VERSION ""

NS_ :

BS_:

BU_: Instruments

BO_ 1522 AC_HSC1_FrP00: 1 Vector__XXX
 SG_ keep_network_AC_HS : 0|1@0+ (1,0) [0|1] ""  Instruments
 SG_ keep_network_AC_HS_UB : 1|1@0+ (1,0) [0|1] ""  Instruments

BO_ 1205 AC_HSC1_FrS01: 1 Vector__XXX
 SG_ wake_network_AC_HS : 0|1@0+ (1,0) [0|1] ""  Instruments
 SG_ wake_network_AC_HS_UB : 1|1@0+ (1,0) [0|1] ""  Instruments

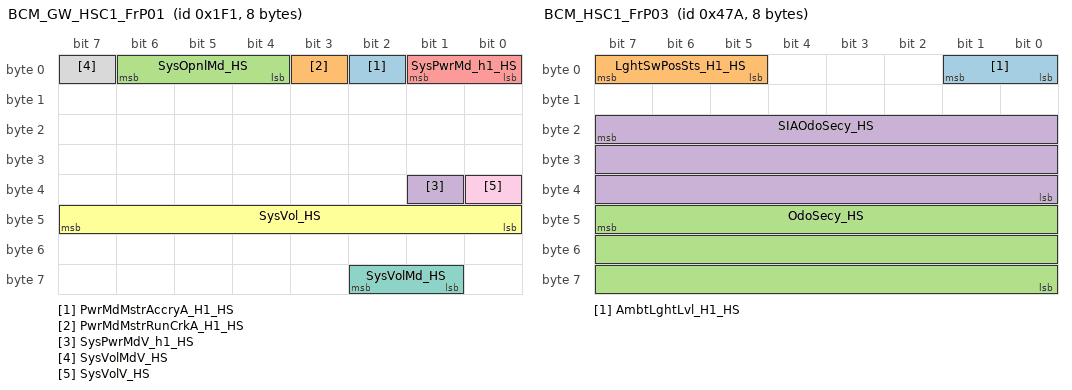
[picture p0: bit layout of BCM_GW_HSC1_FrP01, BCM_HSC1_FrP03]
BO_ 497 BCM_GW_HSC1_FrP01: 8 Vector__XXX
 SG_ PwrMdMstrAccryA_H1_HS : 2|1@0+ (1,0) [0|1] ""  Instruments
 SG_ PwrMdMstrRunCrkA_H1_HS : 3|1@0+ (1,0) [0|1] ""  Instruments
 SG_ SysOpnlMd_HS : 6|3@0+ (1,0) [0|7] ""  Instruments
 SG_ SysPwrMdV_h1_HS : 33|1@0+ (1,0) [0|1] ""  Instruments
 SG_ SysPwrMd_h1_HS : 1|2@0+ (1,0) [0|3] ""  Instruments
 SG_ SysVol_HS : 47|8@0+ (0.1,3) [3|28.5] "V"  Instruments
 SG_ SysVolMd_HS : 58|2@0+ (1,0) [0|3] ""  Instruments
 SG_ SysVolMdV_HS : 7|1@0+ (1,0) [0|1] ""  Instruments
 SG_ SysVolV_HS : 32|1@0+ (1,0) [0|1] ""  Instruments

BO_ 1344 BCM_GW_HSC1_FrP07: 8 Vector__XXX
 SG_ VehOdoV_H1_HS : 31|1@0+ (1,0) [0|1] ""  Instruments
 SG_ VehOdo_H1_HS : 7|24@0+ (1,0) [0|16777200] ""  Instruments

BO_ 795 BCM_GW_HSC1_FrP09: 8 Vector__XXX
 SG_ PwrMdMstrAccryWkupA_HS : 22|1@0+ (1,0) [0|1] ""  Instruments
 SG_ PwrMdMstrIgnA_HS : 23|1@0+ (1,0) [0|1] ""  Instruments

BO_ 1055 BCM_HSC1_FrI01: 3 Vector__XXX
 SG_ network_mode : 7|8@0+ (1,0) [0|255] ""  Instruments
 SG_ signal_config_id : 15|16@0+ (1,0) [0|65535] ""  Instruments

BO_ 1139 BCM_HSC1_FrP02: 8 Vector__XXX
 SG_ VINBCM_H1_HS : 7|64@0+ (1,0) [0|0] ""  Instruments

BO_ 1146 BCM_HSC1_FrP03: 8 Vector__XXX
 SG_ AmbtLghtLvl_H1_HS : 1|2@0+ (1,0) [0|3] ""  Instruments
 SG_ LghtSwPosSts_H1_HS : 7|3@0+ (1,0) [0|7] ""  Instruments
 SG_ OdoSecy_HS : 47|24@0+ (1,0) [0|16777200] "km"  Instruments
 SG_ SIAOdoSecy_HS : 23|24@0+ (1,0) [0|16777200] "km"  Instruments

BO_ 1130 BCM_HSC1_FrP04: 8 Vector__XXX
 SG_ BCMEmgcSp_HS : 56|1@0+ (1,0) [0|1] ""  Instruments
 SG_ BCMPwrMdHwdSta_HS : 50|2@0+ (1,0) [0|3] ""  Instruments
 SG_ BCMPwrMdHwdStaV_HS : 48|1@0+ (1,0) [0|1] ""  Instruments
 SG_ BCMSSBA_HS : 57|1@0+ (1,0) [0|1] ""  Instruments
 SG_ BCMSSBAV_HS : 58|1@0+ (1,0) [0|1] ""  Instruments
 SG_ BntOpenSts_H1_HS : 45|2@0+ (1,0) [0|3] ""  Instruments
 SG_ DipdBeamLghtOn_HS : 63|1@0+ (1,0) [0|1] ""  Instruments
 SG_ DrvrDoorOpenSts_H1_HS : 47|2@0+ (1,0) [0|3] ""  Instruments
 SG_ FrtFogLghtOn_H1_HS : 62|1@0+ (1,0) [0|1] ""  Instruments
 SG_ FrtPsngDoorOpenSts_H1_HS : 43|2@0+ (1,0) [0|3] ""  Instruments
 SG_ LDircnIO_HS : 37|1@0+ (1,0) [0|1] ""  Instruments
 SG_ LdspcOpenSts_H1_HS : 33|2@0+ (1,0) [0|3] ""  Instruments
 SG_ MainBeamLghtOn_H1_HS : 36|1@0+ (1,0) [0|1] ""  Instruments
 SG_ RDircnIO_HS : 38|1@0+ (1,0) [0|1] ""  Instruments
 SG_ RRDoorOpenSts_HS : 41|2@0+ (1,0) [0|3] ""  Instruments
 SG_ RrFogLghtF_H1_HS : 35|1@0+ (1,0) [0|1] ""  Instruments
 SG_ RrFogLghtOn_H1_HS : 39|1@0+ (1,0) [0|1] ""  Instruments
 SG_ VehLckngSta_H1_HS : 55|3@0+ (1,0) [0|7] ""  Instruments
 SG_ VehSideLghtSts_H1_HS : 52|2@0+ (1,0) [0|3] ""  Instruments

BO_ 540 BCM_HSC1_FrP06: 8 Vector__XXX
 SG_ BCMGearShftParkNtrlESR_HS : 24|1@0+ (1,0) [0|1] ""  Instruments
 SG_ BCMNoSmtKeyInVehRmndr_HS : 13|1@0+ (1,0) [0|1] ""  Instruments
 SG_ BCMNoSmtKeyPressBrkTRR_HS : 15|1@0+ (1,0) [0|1] ""  Instruments
 SG_ BCMNoSmtKeyPressClToRR_HS : 14|1@0+ (1,0) [0|1] ""  Instruments
 SG_ BCMPressBrkRmndr_HS : 28|1@0+ (1,0) [0|1] ""  Instruments
 SG_ BCMPressClRmndr_HS : 27|1@0+ (1,0) [0|1] ""  Instruments
 SG_ BCMPutSmtKeyToBkupPosR_HS : 12|1@0+ (1,0) [0|1] ""  Instruments
 SG_ BCMRunCrkF_HS : 56|1@0+ (1,0) [0|1] ""  Instruments
 SG_ BCMShftParkRmndr_HS : 38|1@0+ (1,0) [0|1] ""  Instruments
 SG_ BCMSSBFltSts_HS : 7|3@0+ (1,0) [0|7] ""  Instruments
 SG_ BCMTakeSmtKeyOutOfSR_HS : 26|1@0+ (1,0) [0|1] ""  Instruments
 SG_ DayTimeRunningLghtF_HS : 30|1@0+ (1,0) [0|1] ""  Instruments
 SG_ DrvrWndOpenRmndr_HS : 11|1@0+ (1,0) [0|1] ""  Instruments
 SG_ FrtSideLghtF_HS : 52|1@0+ (1,0) [0|1] ""  Instruments
 SG_ LBrkLghtF_HS : 23|1@0+ (1,0) [0|1] ""  Instruments
 SG_ LDipdBeamLghtF_HS : 22|1@0+ (1,0) [0|1] ""  Instruments
 SG_ LDircnIndLghtF_H1_HS : 21|1@0+ (1,0) [0|1] ""  Instruments
 SG_ PEPSAntFlt_HS : 57|1@0+ (1,0) [0|1] ""  Instruments
 SG_ RBrkLghtF_HS : 19|1@0+ (1,0) [0|1] ""  Instruments
 SG_ RDipdBeamLghtF_HS : 18|1@0+ (1,0) [0|1] ""  Instruments
 SG_ RDircnIndLghtF_H1_HS : 17|1@0+ (1,0) [0|1] ""  Instruments
 SG_ RevsLghtF_H1_HS : 31|1@0+ (1,0) [0|1] ""  Instruments
 SG_ RrSideLghtF_HS : 53|1@0+ (1,0) [0|1] ""  Instruments
 SG_ ScurtAlrmSts_HS : 2|3@0+ (1,0) [0|7] ""  Instruments
 SG_ ScurtKeyBatLow_HS : 3|1@0+ (1,0) [0|1] ""  Instruments
 SG_ ScurtKeyInvd_HS : 35|1@0+ (1,0) [0|1] ""  Instruments
 SG_ ShifterLckRlseBrkReqA_HS : 39|1@0+ (1,0) [0|1] ""  Instruments
 SG_ SrfOpenRmndr_HS : 8|1@0+ (1,0) [0|1] ""  Instruments
 SG_ SSBEnOffRmndr_HS : 33|2@0+ (1,0) [0|3] ""  Instruments
 SG_ TakeKeyOutRmndr_HS : 25|1@0+ (1,0) [0|1] ""  Instruments

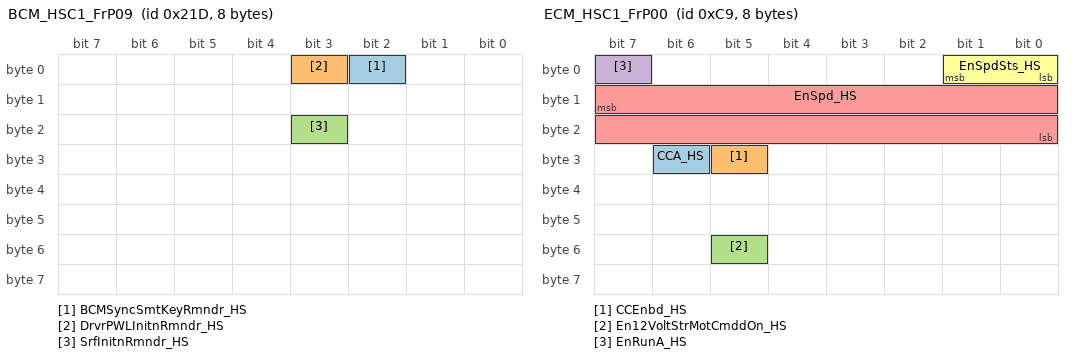
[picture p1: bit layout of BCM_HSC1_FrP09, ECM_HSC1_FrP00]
BO_ 541 BCM_HSC1_FrP09: 8 Vector__XXX
 SG_ BCMSyncSmtKeyRmndr_HS : 2|1@0+ (1,0) [0|1] ""  Instruments
 SG_ DrvrPWLInitnRmndr_HS : 3|1@0+ (1,0) [0|1] ""  Instruments
 SG_ SrfInitnRmndr_HS : 19|1@0+ (1,0) [0|1] ""  Instruments

BO_ 793 BCM_PMDC_HSC1_FrP01: 8 Vector__XXX
 SG_ BatVol_HS : 37|14@0+ (0.00097656,3) [3|18] "V"  Instruments

BO_ 814 BCM_PMDC_HSC1_FrP02: 8 Vector__XXX
 SG_ BatAgngSta_HS : 23|3@0+ (1,0) [0|7] ""  Instruments
 SG_ GenrSta_HS : 7|3@0+ (1,0) [0|7] ""  Instruments

BO_ 1303 BCM_PMDC_HSC1_FrP03: 8 Vector__XXX
 SG_ BatSOC_HS : 15|8@0+ (0.4,0) [0|100] "%"  Instruments
 SG_ VehLdShedLvl_H1_HS : 23|3@0+ (1,0) [0|7] ""  Instruments

BO_ 845 BCM_TBOX_HSC1_FrP01: 8 Vector__XXX
 SG_ EmgcCallFlrSts_HS : 17|2@0+ (1,0) [0|3] ""  Instruments

BO_ 1976 DIAG_DTCInfo_IPK: 7 Instruments
 SG_ DTCInfomationIPK_HS : 7|56@0+ (1,0) [0|0] "" Vector__XXX

BO_ 2015 DIAG_FuncReq_HSC1: 8 Vector__XXX
 SG_ DiagnosticFuncAddrReq : 7|64@0+ (1,0) [0|0] ""  Instruments

BO_ 1888 DIAG_PhysReq_IPK: 8 Vector__XXX
 SG_ DiagnosticReqIPK : 7|64@0+ (1,0) [0|0] ""  Instruments

BO_ 1896 DIAG_PhysResp_IPK: 8 Instruments
 SG_ DiagnosticRespIPK : 7|64@0+ (1,0) [0|0] "" Vector__XXX

BO_ 1546 DIAG_Req_VKR: 8 Vector__XXX
 SG_ DiagnosticReqVKR : 7|64@0+ (1,0) [0|0] ""  Instruments

BO_ 1547 DIAG_Resp_VKR: 8 Instruments
 SG_ DiagnosticRespVKR : 7|64@0+ (1,0) [0|0] "" Vector__XXX

BO_ 201 ECM_HSC1_FrP00: 8 Vector__XXX
 SG_ CCA_HS : 30|1@0+ (1,0) [0|1] ""  Instruments
 SG_ CCEnbd_HS : 29|1@0+ (1,0) [0|1] ""  Instruments
 SG_ En12VoltStrMotCmddOn_HS : 53|1@0+ (1,0) [0|1] ""  Instruments
 SG_ EnRunA_HS : 7|1@0+ (1,0) [0|1] ""  Instruments
 SG_ EnSpd_HS : 15|16@0+ (0.25,0) [0|16383.8] "rpm"  Instruments
 SG_ EnSpdSts_HS : 1|2@0+ (1,0) [0|3] ""  Instruments

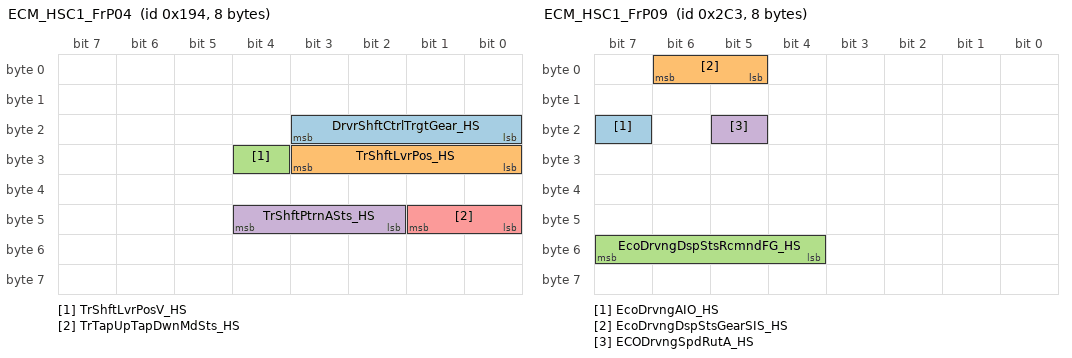
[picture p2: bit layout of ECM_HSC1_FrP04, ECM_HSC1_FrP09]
BO_ 404 ECM_HSC1_FrP04: 8 Vector__XXX
 SG_ DrvrShftCtrlTrgtGear_HS : 19|4@0+ (1,0) [0|15] ""  Instruments
 SG_ TrShftLvrPos_HS : 27|4@0+ (1,0) [0|15] ""  Instruments
 SG_ TrShftLvrPosV_HS : 28|1@0+ (1,0) [0|1] ""  Instruments
 SG_ TrShftPtrnASts_HS : 44|3@0+ (1,0) [0|7] ""  Instruments
 SG_ TrTapUpTapDwnMdSts_HS : 41|2@0+ (1,0) [0|3] ""  Instruments

BO_ 479 ECM_HSC1_FrP07: 2 Vector__XXX
 SG_ EnASSSta_HS : 1|2@0+ (1,0) [0|3] ""  Instruments

BO_ 707 ECM_HSC1_FrP09: 8 Vector__XXX
 SG_ EcoDrvngAIO_HS : 23|1@0+ (1,0) [0|1] ""  Instruments
 SG_ EcoDrvngDspStsGearSIS_HS : 6|2@0+ (1,0) [0|3] ""  Instruments
 SG_ EcoDrvngDspStsRcmndFG_HS : 55|4@0+ (1,0) [0|15] ""  Instruments
 SG_ ECODrvngSpdRutA_HS : 21|1@0+ (1,0) [0|1] ""  Instruments

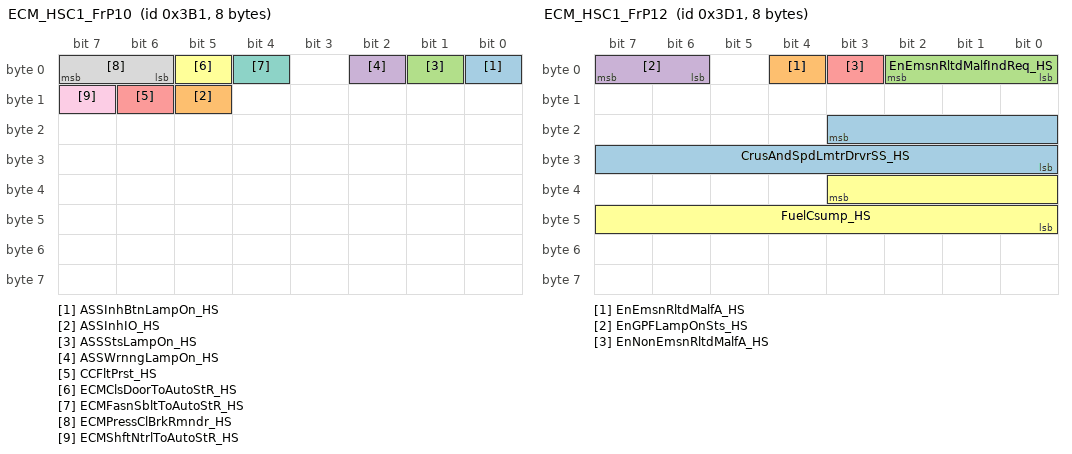
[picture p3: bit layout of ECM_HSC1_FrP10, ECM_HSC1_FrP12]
BO_ 945 ECM_HSC1_FrP10: 8 Vector__XXX
 SG_ ASSInhBtnLampOn_HS : 0|1@0+ (1,0) [0|1] ""  Instruments
 SG_ ASSInhIO_HS : 13|1@0+ (1,0) [0|1] ""  Instruments
 SG_ ASSStsLampOn_HS : 1|1@0+ (1,0) [0|1] ""  Instruments
 SG_ ASSWrnngLampOn_HS : 2|1@0+ (1,0) [0|1] ""  Instruments
 SG_ CCFltPrst_HS : 14|1@0+ (1,0) [0|1] ""  Instruments
 SG_ ECMClsDoorToAutoStR_HS : 5|1@0+ (1,0) [0|1] ""  Instruments
 SG_ ECMFasnSbltToAutoStR_HS : 4|1@0+ (1,0) [0|1] ""  Instruments
 SG_ ECMPressClBrkRmndr_HS : 7|2@0+ (1,0) [0|3] ""  Instruments
 SG_ ECMShftNtrlToAutoStR_HS : 15|1@0+ (1,0) [0|1] ""  Instruments

BO_ 977 ECM_HSC1_FrP12: 8 Vector__XXX
 SG_ CrusAndSpdLmtrDrvrSS_HS : 19|12@0+ (0.0625,0) [0|255.938] ""  Instruments
 SG_ EnEmsnRltdMalfA_HS : 4|1@0+ (1,0) [0|1] ""  Instruments
 SG_ EnEmsnRltdMalfIndReq_HS : 2|3@0+ (1,0) [0|7] ""  Instruments
 SG_ EnGPFLampOnSts_HS : 7|2@0+ (1,0) [0|3] ""  Instruments
 SG_ EnNonEmsnRltdMalfA_HS : 3|1@0+ (1,0) [0|1] ""  Instruments
 SG_ FuelCsump_HS : 35|12@0+ (16,0) [0|65520] "microlitre"  Instruments

BO_ 1217 ECM_HSC1_FrP14: 8 Vector__XXX
 SG_ EnClntTem_HS : 23|8@0+ (1,-40) [-40|215] "deg C"  Instruments
 SG_ EnClntTemV_HS : 6|1@0+ (1,0) [0|1] ""  Instruments

BO_ 1233 ECM_HSC1_FrP15: 8 Vector__XXX
 SG_ EnOilPrsLowIO_HS : 5|1@0+ (1,0) [0|1] ""  Instruments

BO_ 251 ECM_HSC1_FrP27: 8 Vector__XXX
 SG_ SpdAstSysStsECM_HS : 18|3@0+ (1,0) [0|7] ""  Instruments
 SG_ SpdAstSysTrgtSpd_HS : 30|15@0+ (0.015625,0) [0|511.984] ""  Instruments

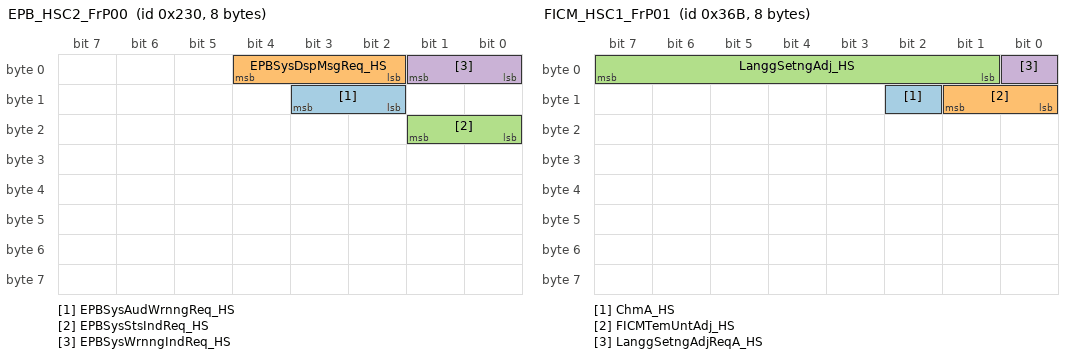
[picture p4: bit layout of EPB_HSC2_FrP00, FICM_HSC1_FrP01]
BO_ 560 EPB_HSC2_FrP00: 8 Vector__XXX
 SG_ EPBSysAudWrnngReq_HS : 11|2@0+ (1,0) [0|3] ""  Instruments
 SG_ EPBSysDspMsgReq_HS : 4|3@0+ (1,0) [0|7] ""  Instruments
 SG_ EPBSysStsIndReq_HS : 17|2@0+ (1,0) [0|3] ""  Instruments
 SG_ EPBSysWrnngIndReq_HS : 1|2@0+ (1,0) [0|3] ""  Instruments

BO_ 328 EPS_HSC1_FrP00: 1 Vector__XXX
 SG_ EPSFlrSts_HS : 7|2@0+ (1,0) [0|3] ""  Instruments

BO_ 1071 ESCL_HSC1_FrP00: 1 Vector__XXX
 SG_ keep_network_ESCL_HS : 0|1@0+ (1,0) [0|1] ""  Instruments
 SG_ keep_network_ESCL_HS_UB : 1|1@0+ (1,0) [0|1] ""  Instruments

BO_ 1127 ESCL_HSC1_FrP01: 4 Vector__XXX
 SG_ ESCLFlrIndCmd_HS : 25|2@0+ (1,0) [0|3] ""  Instruments

BO_ 1059 ESCL_HSC1_FrS04: 1 Vector__XXX
 SG_ wake_network_ESCL_HS : 0|1@0+ (1,0) [0|1] ""  Instruments
 SG_ wake_network_ESCL_HS_UB : 1|1@0+ (1,0) [0|1] ""  Instruments

BO_ 1104 FICM_HSC1_FrP00: 1 Vector__XXX
 SG_ keep_network_FICM_HS : 0|1@0+ (1,0) [0|1] ""  Instruments
 SG_ keep_network_FICM_HS_UB : 1|1@0+ (1,0) [0|1] ""  Instruments

BO_ 875 FICM_HSC1_FrP01: 8 Vector__XXX
 SG_ ChmA_HS : 10|1@0+ (1,0) [0|1] ""  Instruments
 SG_ FICMTemUntAdj_HS : 9|2@0+ (1,0) [0|3] ""  Instruments
 SG_ LanggSetngAdj_HS : 7|7@0+ (1,0) [0|127] ""  Instruments
 SG_ LanggSetngAdjReqA_HS : 0|1@0+ (1,0) [0|1] ""  Instruments

BO_ 886 FICM_HSC1_FrP02: 8 Vector__XXX
 SG_ FICMDistUnitAdjtReqA_HS : 62|1@0+ (1,0) [0|1] ""  Instruments

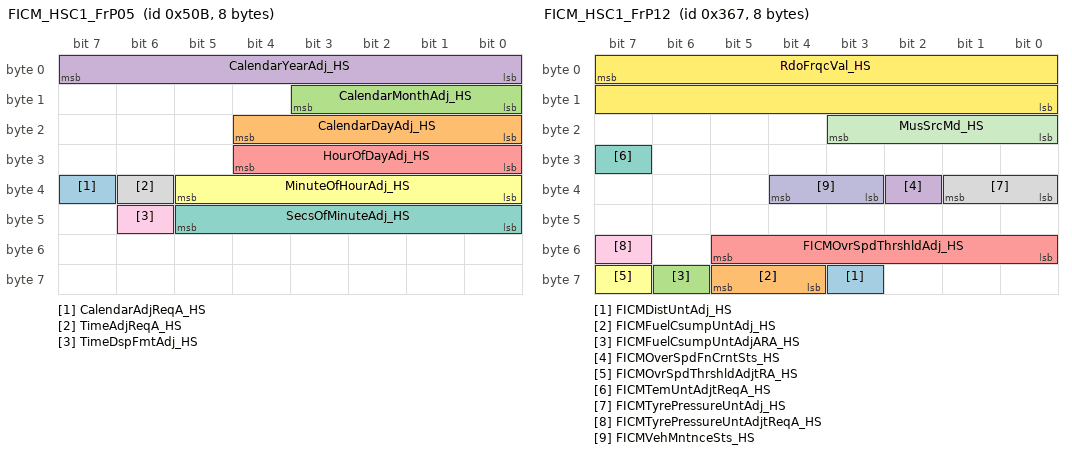
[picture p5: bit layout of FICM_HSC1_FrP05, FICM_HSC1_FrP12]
BO_ 1291 FICM_HSC1_FrP05: 8 Vector__XXX
 SG_ CalendarAdjReqA_HS : 39|1@0+ (1,0) [0|1] ""  Instruments
 SG_ CalendarDayAdj_HS : 20|5@0+ (1,0) [0|31] ""  Instruments
 SG_ CalendarMonthAdj_HS : 11|4@0+ (1,0) [0|15] ""  Instruments
 SG_ CalendarYearAdj_HS : 7|8@0+ (1,2000) [2000|2255] ""  Instruments
 SG_ HourOfDayAdj_HS : 28|5@0+ (1,0) [0|23] ""  Instruments
 SG_ MinuteOfHourAdj_HS : 37|6@0+ (1,0) [0|59] ""  Instruments
 SG_ SecsOfMinuteAdj_HS : 45|6@0+ (1,0) [0|59] ""  Instruments
 SG_ TimeAdjReqA_HS : 38|1@0+ (1,0) [0|1] ""  Instruments
 SG_ TimeDspFmtAdj_HS : 46|1@0+ (1,0) [0|1] ""  Instruments

BO_ 871 FICM_HSC1_FrP12: 8 Vector__XXX
 SG_ FICMDistUntAdj_HS : 59|1@0+ (1,0) [0|1] ""  Instruments
 SG_ FICMFuelCsumpUntAdj_HS : 61|2@0+ (1,0) [0|3] ""  Instruments
 SG_ FICMFuelCsumpUntAdjARA_HS : 62|1@0+ (1,0) [0|1] ""  Instruments
 SG_ FICMOverSpdFnCrntSts_HS : 34|1@0+ (1,0) [0|1] ""  Instruments
 SG_ FICMOvrSpdThrshldAdj_HS : 53|6@0+ (5,0) [0|315] ""  Instruments
 SG_ FICMOvrSpdThrshldAdjtRA_HS : 63|1@0+ (1,0) [0|1] ""  Instruments
 SG_ FICMTemUntAdjtReqA_HS : 31|1@0+ (1,0) [0|1] ""  Instruments
 SG_ FICMTyrePressureUntAdj_HS : 33|2@0+ (1,0) [0|3] ""  Instruments
 SG_ FICMTyrePressureUntAdjtReqA_HS : 55|1@0+ (1,0) [0|1] ""  Instruments
 SG_ FICMVehMntnceSts_HS : 36|2@0+ (1,0) [0|3] ""  Instruments
 SG_ MusSrcMd_HS : 19|4@0+ (1,0) [0|15] ""  Instruments
 SG_ RdoFrqcVal_HS : 7|16@0+ (0.1,0) [0|6553.4] ""  Instruments

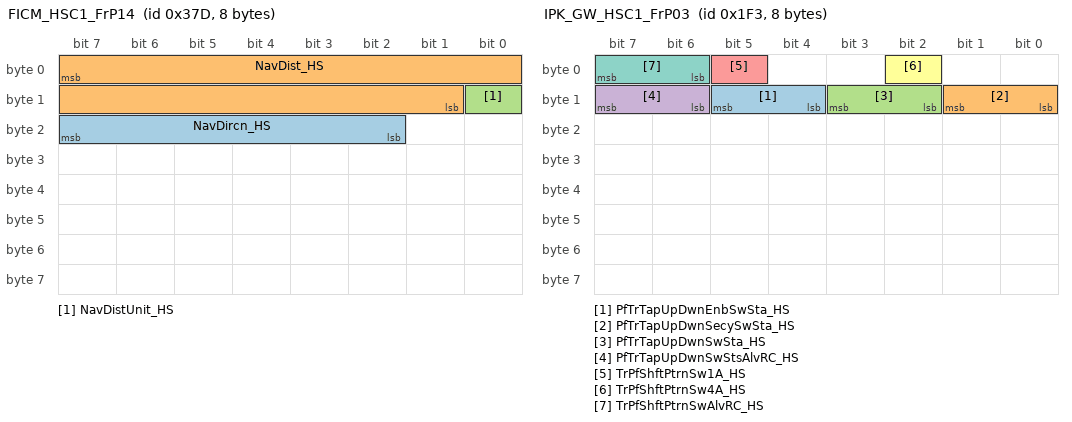
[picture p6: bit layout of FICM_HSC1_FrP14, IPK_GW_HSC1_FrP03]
BO_ 893 FICM_HSC1_FrP14: 8 Vector__XXX
 SG_ NavDircn_HS : 23|6@0+ (1,0) [0|63] ""  Instruments
 SG_ NavDist_HS : 7|15@0+ (1,0) [0|32767] ""  Instruments
 SG_ NavDistUnit_HS : 8|1@0+ (1,0) [0|1] ""  Instruments

BO_ 1095 FICM_HSC1_FrS00: 1 Vector__XXX
 SG_ wake_network_FICM_HS : 0|1@0+ (1,0) [0|1] ""  Instruments
 SG_ wake_network_FICM_HS_UB : 1|1@0+ (1,0) [0|1] ""  Instruments

BO_ 217 IPK_BCM_HSC1_FrP05: 8 Instruments
 SG_ ASSInhBtnA_HS : 41|1@0+ (1,0) [0|1] "" Vector__XXX

BO_ 498 IPK_BCM_HSC1_FrP07: 2 Instruments
 SG_ SysBPM_HS : 5|2@0+ (1,0) [0|3] "" Vector__XXX
 SG_ SysBPMEnbd_HS : 6|1@0+ (1,0) [0|1] "" Vector__XXX

BO_ 499 IPK_GW_HSC1_FrP03: 8 Instruments
 SG_ PfTrTapUpDwnEnbSwSta_HS : 13|2@0+ (1,0) [0|3] "" Vector__XXX
 SG_ PfTrTapUpDwnSecySwSta_HS : 9|2@0+ (1,0) [0|3] "" Vector__XXX
 SG_ PfTrTapUpDwnSwSta_HS : 11|2@0+ (1,0) [0|3] "" Vector__XXX
 SG_ PfTrTapUpDwnSwStsAlvRC_HS : 15|2@0+ (1,0) [0|3] "" Vector__XXX
 SG_ TrPfShftPtrnSw1A_HS : 5|1@0+ (1,0) [0|1] "" Vector__XXX
 SG_ TrPfShftPtrnSw4A_HS : 2|1@0+ (1,0) [0|1] "" Vector__XXX
 SG_ TrPfShftPtrnSwAlvRC_HS : 7|2@0+ (1,0) [0|3] "" Vector__XXX

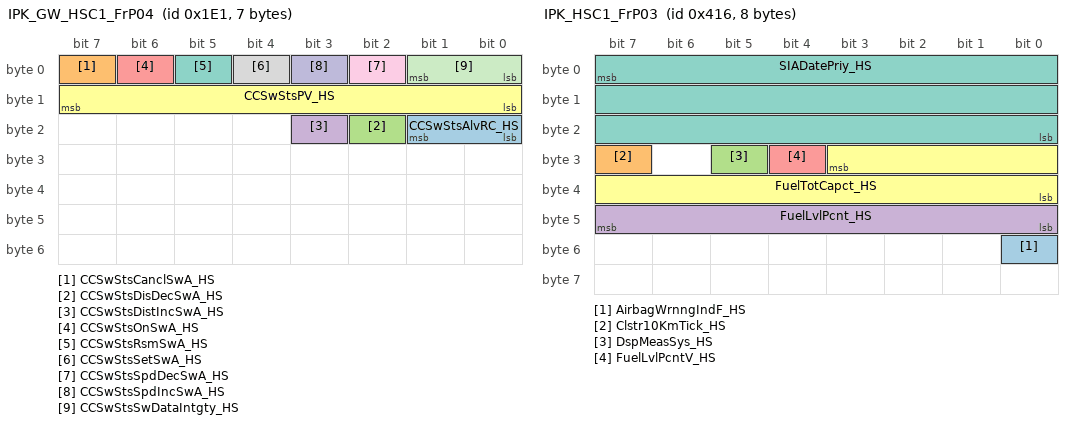
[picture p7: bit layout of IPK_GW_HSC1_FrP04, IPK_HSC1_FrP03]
BO_ 481 IPK_GW_HSC1_FrP04: 7 Instruments
 SG_ CCSwStsAlvRC_HS : 17|2@0+ (1,0) [0|3] "" Vector__XXX
 SG_ CCSwStsCanclSwA_HS : 7|1@0+ (1,0) [0|1] "" Vector__XXX
 SG_ CCSwStsDisDecSwA_HS : 18|1@0+ (1,0) [0|1] "" Vector__XXX
 SG_ CCSwStsDistIncSwA_HS : 19|1@0+ (1,0) [0|1] "" Vector__XXX
 SG_ CCSwStsOnSwA_HS : 6|1@0+ (1,0) [0|1] "" Vector__XXX
 SG_ CCSwStsPV_HS : 15|8@0+ (1,0) [0|255] "" Vector__XXX
 SG_ CCSwStsRsmSwA_HS : 5|1@0+ (1,0) [0|1] "" Vector__XXX
 SG_ CCSwStsSetSwA_HS : 4|1@0+ (1,0) [0|1] "" Vector__XXX
 SG_ CCSwStsSpdDecSwA_HS : 2|1@0+ (1,0) [0|1] "" Vector__XXX
 SG_ CCSwStsSpdIncSwA_HS : 3|1@0+ (1,0) [0|1] "" Vector__XXX
 SG_ CCSwStsSwDataIntgty_HS : 1|2@0+ (1,0) [0|3] "" Vector__XXX

BO_ 1523 IPK_HSC1_FrP00: 1 Instruments
 SG_ keep_network_IPK_HS : 0|1@0+ (1,0) [0|1] "" Vector__XXX
 SG_ keep_network_IPK_HS_UB : 1|1@0+ (1,0) [0|1] "" Vector__XXX

BO_ 1142 IPK_HSC1_FrP01: 8 Instruments
 SG_ VINClstr_HS : 7|64@0+ (1,0) [0|0] "" Vector__XXX

BO_ 1046 IPK_HSC1_FrP03: 8 Instruments
 SG_ AirbagWrnngIndF_HS : 48|1@0+ (1,0) [0|1] "" Vector__XXX
 SG_ Clstr10KmTick_HS : 31|1@0+ (1,0) [0|1] "" Vector__XXX
 SG_ DspMeasSys_HS : 29|1@0+ (1,0) [0|1] "" Vector__XXX
 SG_ FuelLvlPcnt_HS : 47|8@0+ (0.392156,0) [0|99.9998] "%" Vector__XXX
 SG_ FuelLvlPcntV_HS : 28|1@0+ (1,0) [0|1] "" Vector__XXX
 SG_ FuelTotCapct_HS : 27|12@0+ (0.125,0) [0|511.875] "" Vector__XXX
 SG_ SIADatePriy_HS : 7|24@0+ (1,0) [0|0] "" Vector__XXX

BO_ 858 IPK_HSC1_FrP04: 8 Instruments
 SG_ AvgFuelCsump_HS : 63|8@0+ (0.1,0) [0|25.5] "L/100 km" Vector__XXX
 SG_ AvgFuelCsumpV_HS : 24|1@0+ (1,0) [0|1] "" Vector__XXX
 SG_ ChmCmdSndCndcPrd_HS : 7|8@0+ (10,0) [0|2550] "" Vector__XXX
 SG_ ChmCmdSndDutyCyc_HS : 15|8@0+ (0.392157,0) [0|100] "" Vector__XXX
 SG_ ChmCmdSndLoctnFL_HS : 16|1@0+ (1,0) [0|1] "" Vector__XXX
 SG_ ChmCmdSndLoctnFR_HS : 17|1@0+ (1,0) [0|1] "" Vector__XXX
 SG_ ChmCmdSndLoctnRL_HS : 18|1@0+ (1,0) [0|1] "" Vector__XXX
 SG_ ChmCmdSndLoctnRR_HS : 19|1@0+ (1,0) [0|1] "" Vector__XXX
 SG_ ChmCmdSndTone_HS : 23|4@0+ (1,0) [0|15] "" Vector__XXX
 SG_ ClstrDspdVehSpd_HS : 47|8@0+ (1,0) [0|254] "km/h" Vector__XXX
 SG_ IPCAccryA_HS : 48|1@0+ (1,0) [0|1] "" Vector__XXX
 SG_ IPCRunCrkA_HS : 49|1@0+ (1,0) [0|1] "" Vector__XXX
 SG_ IPCRunCrkF_HS : 50|1@0+ (1,0) [0|1] "" Vector__XXX
 SG_ IPCSSBA_HS : 51|1@0+ (1,0) [0|1] "" Vector__XXX
 SG_ IPCSSBAV_HS : 52|1@0+ (1,0) [0|1] "" Vector__XXX
 SG_ IPCSSBFltSts_HS : 55|3@0+ (1,0) [0|7] "" Vector__XXX
 SG_ LanggSetng_HS : 31|7@0+ (1,0) [0|127] "" Vector__XXX

BO_ 1134 IPK_HSC1_FrP05: 8 Instruments
 SG_ OdoPriy_HS : 23|24@0+ (1,0) [0|16777200] "km" Vector__XXX
 SG_ SIAOdoPriy_HS : 47|24@0+ (1,0) [0|16777200] "km" Vector__XXX

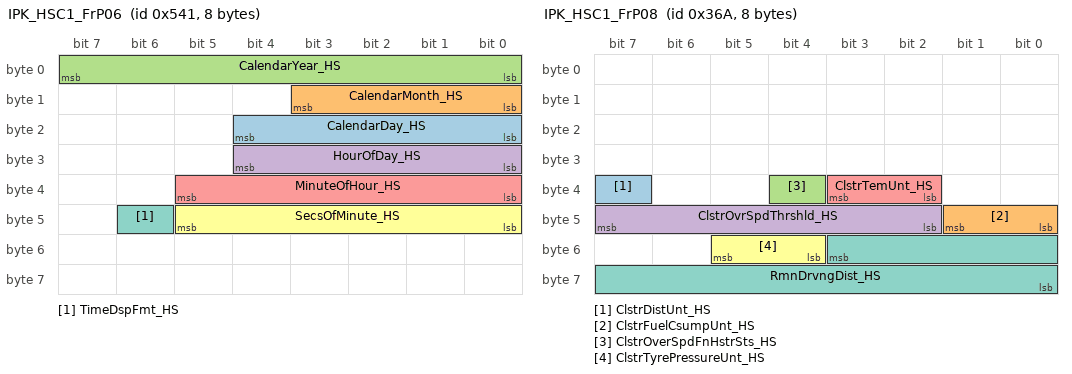
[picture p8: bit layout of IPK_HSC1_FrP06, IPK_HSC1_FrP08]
BO_ 1345 IPK_HSC1_FrP06: 8 Instruments
 SG_ CalendarDay_HS : 20|5@0+ (1,0) [0|31] "" Vector__XXX
 SG_ CalendarMonth_HS : 11|4@0+ (1,0) [0|15] "" Vector__XXX
 SG_ CalendarYear_HS : 7|8@0+ (1,2000) [2000|2255] "" Vector__XXX
 SG_ HourOfDay_HS : 28|5@0+ (1,0) [0|23] "" Vector__XXX
 SG_ MinuteOfHour_HS : 37|6@0+ (1,0) [0|59] "" Vector__XXX
 SG_ SecsOfMinute_HS : 45|6@0+ (1,0) [0|59] "" Vector__XXX
 SG_ TimeDspFmt_HS : 46|1@0+ (1,0) [0|1] "" Vector__XXX

BO_ 1123 IPK_HSC1_FrP07: 4 Instruments
 SG_ IPCEcoDrvngSwA_HS : 26|1@0+ (1,0) [0|1] "" Vector__XXX

BO_ 874 IPK_HSC1_FrP08: 8 Instruments
 SG_ ClstrDistUnt_HS : 39|1@0+ (1,0) [0|1] "" Vector__XXX
 SG_ ClstrFuelCsumpUnt_HS : 41|2@0+ (1,0) [0|3] "" Vector__XXX
 SG_ ClstrOverSpdFnHstrSts_HS : 36|1@0+ (1,0) [0|1] "" Vector__XXX
 SG_ ClstrOvrSpdThrshld_HS : 47|6@0+ (5,0) [0|315] "" Vector__XXX
 SG_ ClstrTemUnt_HS : 35|2@0+ (1,0) [0|3] "" Vector__XXX
 SG_ ClstrTyrePressureUnt_HS : 53|2@0+ (1,0) [0|3] "" Vector__XXX
 SG_ RmnDrvngDist_HS : 51|12@0+ (1,0) [0|4095] "km" Vector__XXX

BO_ 1047 IPK_HSC1_FrP09: 8 Instruments
 SG_ ClstrDspdABSWrnng_HS : 41|1@0+ (1,0) [0|1] "" Vector__XXX
 SG_ ClstrDspdAirbagWrnng_HS : 27|1@0+ (1,0) [0|1] "" Vector__XXX
 SG_ ClstrDspdAltrWrnng_HS : 36|1@0+ (1,0) [0|1] "" Vector__XXX
 SG_ ClstrDspdASpdLmtrWrnng_HS : 24|1@0+ (1,0) [0|1] "" Vector__XXX
 SG_ ClstrDspdAutoholdWrnng_HS : 2|1@0+ (1,0) [0|1] "" Vector__XXX
 SG_ ClstrDspdBatRplmntRqdW_HS : 18|1@0+ (1,0) [0|1] "" Vector__XXX
 SG_ ClstrDspdBrkSysWrnng_HS : 43|1@0+ (1,0) [0|1] "" Vector__XXX
 SG_ ClstrDspdCCWrnng_HS : 11|1@0+ (1,0) [0|1] "" Vector__XXX
 SG_ ClstrDspdClntTemWrnng_HS : 42|1@0+ (1,0) [0|1] "" Vector__XXX
 SG_ ClstrDspdClSwWrnng_HS : 30|1@0+ (1,0) [0|1] "" Vector__XXX
 SG_ ClstrDspdDayTimeRLW_HS : 15|1@0+ (1,0) [0|1] "" Vector__XXX
 SG_ ClstrDspdEleccParkngBW_HS : 10|1@0+ (1,0) [0|1] "" Vector__XXX
 SG_ ClstrDspdEnDrvByWireW_HS : 9|1@0+ (1,0) [0|1] "" Vector__XXX
 SG_ ClstrDspdEPSWrnng_HS : 57|2@0+ (1,0) [0|3] "" Vector__XXX
 SG_ ClstrDspdFuelLvlSgmt_HS : 63|4@0+ (1,0) [0|15] "" Vector__XXX
 SG_ ClstrDspdFuelSnsrWrnng_HS : 47|1@0+ (1,0) [0|1] "" Vector__XXX
 SG_ ClstrDspdFuelSts_HS : 46|2@0+ (1,0) [0|3] "" Vector__XXX
 SG_ ClstrDspdHDCWrnng_HS : 39|1@0+ (1,0) [0|1] "" Vector__XXX
 SG_ ClstrDspdIgnRelayWrnng_HS : 16|1@0+ (1,0) [0|1] "" Vector__XXX
 SG_ ClstrDspdInfoMsk_HS : 23|1@0+ (1,0) [0|1] "" Vector__XXX
 SG_ ClstrDspdInvdKeyWrnng_HS : 28|1@0+ (1,0) [0|1] "" Vector__XXX
 SG_ ClstrDspdLBrkLghtWrnng_HS : 48|1@0+ (1,0) [0|1] "" Vector__XXX
 SG_ ClstrDspdLDipdBeamLW_HS : 52|1@0+ (1,0) [0|1] "" Vector__XXX
 SG_ ClstrDspdLDircnIndLW_HS : 50|1@0+ (1,0) [0|1] "" Vector__XXX
 SG_ ClstrDspdLSideLghtW_HS : 13|1@0+ (1,0) [0|1] "" Vector__XXX
 SG_ ClstrDspdMalfIndrLghtW_HS : 8|1@0+ (1,0) [0|1] "" Vector__XXX
 SG_ ClstrDspdOilPrsLowW_HS : 37|1@0+ (1,0) [0|1] "" Vector__XXX
 SG_ ClstrDspdPDCWrnng_HS : 20|1@0+ (1,0) [0|1] "" Vector__XXX
 SG_ ClstrDspdPEWrnng_HS : 4|1@0+ (1,0) [0|1] "" Vector__XXX
 SG_ ClstrDspdRBrkLghtWrnng_HS : 49|1@0+ (1,0) [0|1] "" Vector__XXX
 SG_ ClstrDspdRDipdBeamLW_HS : 53|1@0+ (1,0) [0|1] "" Vector__XXX
 SG_ ClstrDspdRDircnIndLW_HS : 51|1@0+ (1,0) [0|1] "" Vector__XXX
 SG_ ClstrDspdRevsLampWrnng_HS : 1|1@0+ (1,0) [0|1] "" Vector__XXX
 SG_ ClstrDspdRrFogLghtW_HS : 0|1@0+ (1,0) [0|1] "" Vector__XXX
 SG_ ClstrDspdRSideLghtW_HS : 14|1@0+ (1,0) [0|1] "" Vector__XXX
 SG_ ClstrDspdSASUncalWrnng_HS : 26|1@0+ (1,0) [0|1] "" Vector__XXX
 SG_ ClstrDspdSASWrnng_HS : 25|1@0+ (1,0) [0|1] "" Vector__XXX
 SG_ ClstrDspdSCSWrnng_HS : 55|1@0+ (1,0) [0|1] "" Vector__XXX
 SG_ ClstrDspdScurtKeyBatLW_HS : 29|1@0+ (1,0) [0|1] "" Vector__XXX
 SG_ ClstrDspdSpStBtnWrnng_HS : 33|1@0+ (1,0) [0|1] "" Vector__XXX
 SG_ ClstrDspdSpStWrnng_HS : 32|1@0+ (1,0) [0|1] "" Vector__XXX
 SG_ ClstrDspdTCSWrnng_HS : 40|1@0+ (1,0) [0|1] "" Vector__XXX
 SG_ ClstrDspdTrWrnng_HS : 22|1@0+ (1,0) [0|1] "" Vector__XXX
 SG_ ClstrDspdTyrePrsSts_HS : 35|2@0+ (1,0) [0|3] "" Vector__XXX

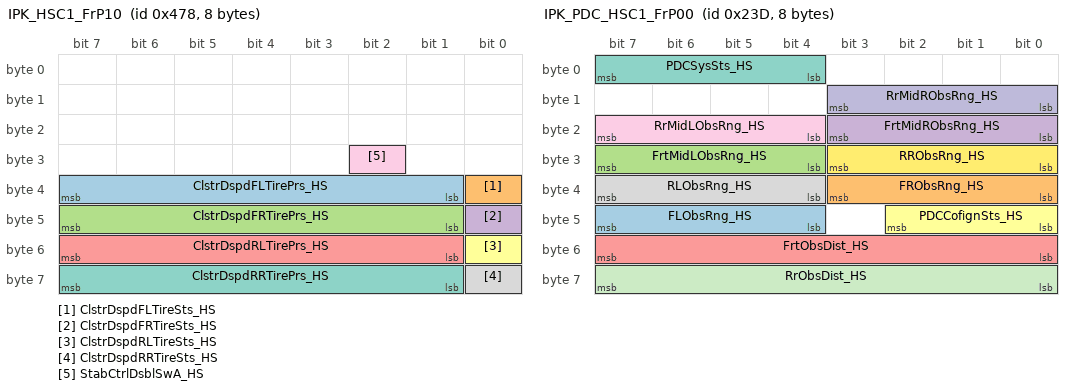
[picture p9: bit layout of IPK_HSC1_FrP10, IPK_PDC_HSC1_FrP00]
BO_ 1144 IPK_HSC1_FrP10: 8 Instruments
 SG_ ClstrDspdFLTirePrs_HS : 39|7@0+ (4,0) [0|508] "kPa" Vector__XXX
 SG_ ClstrDspdFLTireSts_HS : 32|1@0+ (1,0) [0|1] "" Vector__XXX
 SG_ ClstrDspdFRTirePrs_HS : 47|7@0+ (4,0) [0|508] "kPa" Vector__XXX
 SG_ ClstrDspdFRTireSts_HS : 40|1@0+ (1,0) [0|1] "" Vector__XXX
 SG_ ClstrDspdRLTirePrs_HS : 55|7@0+ (4,0) [0|508] "kPa" Vector__XXX
 SG_ ClstrDspdRLTireSts_HS : 48|1@0+ (1,0) [0|1] "" Vector__XXX
 SG_ ClstrDspdRRTirePrs_HS : 63|7@0+ (4,0) [0|508] "kPa" Vector__XXX
 SG_ ClstrDspdRRTireSts_HS : 56|1@0+ (1,0) [0|1] "" Vector__XXX
 SG_ StabCtrlDsblSwA_HS : 26|1@0+ (1,0) [0|1] "" Vector__XXX

BO_ 1531 IPK_HSC1_FS00: 1 Instruments
 SG_ wake_network_IPK_HS : 0|1@0+ (1,0) [0|1] "" Vector__XXX
 SG_ wake_network_IPK_HS_UB : 1|1@0+ (1,0) [0|1] "" Vector__XXX

BO_ 1087 IPK_HSC1_SecNWM: 3 Instruments
 SG_ sm_network_mode_h1 : 7|8@0+ (1,0) [0|255] "" Vector__XXX
 SG_ sm_signal_config_id_h1 : 15|16@0+ (1,0) [0|0] "" Vector__XXX

BO_ 573 IPK_PDC_HSC1_FrP00: 8 Instruments
 SG_ FLObsRng_HS : 47|4@0+ (1,0) [0|15] "" Vector__XXX
 SG_ FRObsRng_HS : 35|4@0+ (1,0) [0|15] "" Vector__XXX
 SG_ FrtMidLObsRng_HS : 31|4@0+ (1,0) [0|15] "" Vector__XXX
 SG_ FrtMidRObsRng_HS : 19|4@0+ (1,0) [0|15] "" Vector__XXX
 SG_ FrtObsDist_HS : 55|8@0+ (1,0) [0|255] "cm" Vector__XXX
 SG_ PDCCofignSts_HS : 42|3@0+ (1,0) [0|7] "" Vector__XXX
 SG_ PDCSysSts_HS : 7|4@0+ (1,0) [0|15] "" Vector__XXX
 SG_ RLObsRng_HS : 39|4@0+ (1,0) [0|15] "" Vector__XXX
 SG_ RrMidLObsRng_HS : 23|4@0+ (1,0) [0|15] "" Vector__XXX
 SG_ RrMidRObsRng_HS : 11|4@0+ (1,0) [0|15] "" Vector__XXX
 SG_ RrObsDist_HS : 63|8@0+ (1,0) [0|255] "cm" Vector__XXX
 SG_ RRObsRng_HS : 27|4@0+ (1,0) [0|15] "" Vector__XXX

BO_ 485 SAS_HSC1_FrP00: 8 Vector__XXX
 SG_ StrgWhlAngSnsrCalSts_HS : 6|2@0+ (1,0) [0|3] ""  Instruments
 SG_ StrgWhlAngSnsrFlt_HS : 0|1@0+ (1,0) [0|1] ""  Instruments

BO_ 455 SCS_HSC1_FrP03: 7 Vector__XXX
 SG_ AutoHoldSysSts_HS : 7|2@0+ (1,0) [0|3] ""  Instruments

BO_ 562 SCS_HSC1_FrP06: 8 Vector__XXX
 SG_ HDCSysSts_HS : 55|3@0+ (1,0) [0|7] ""  Instruments

BO_ 532 SCS_HSC1_FrP09: 6 Vector__XXX
 SG_ BrkFludLvlLow_HS : 6|1@0+ (1,0) [0|1] ""  Instruments
 SG_ BrkFludLvlLowV_HS : 7|1@0+ (1,0) [0|1] ""  Instruments

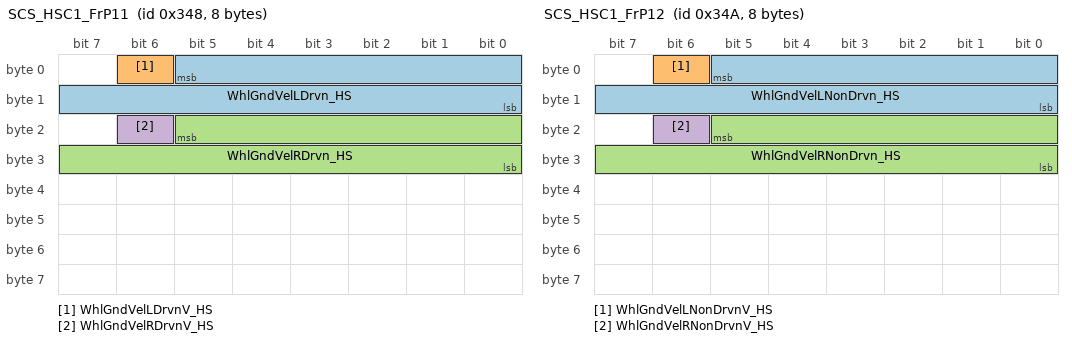
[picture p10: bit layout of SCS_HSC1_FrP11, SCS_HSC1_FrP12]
BO_ 840 SCS_HSC1_FrP11: 8 Vector__XXX
 SG_ WhlGndVelLDrvn_HS : 5|14@0+ (0.03125,0) [0|511.969] "km/h"  Instruments
 SG_ WhlGndVelLDrvnV_HS : 6|1@0+ (1,0) [0|1] ""  Instruments
 SG_ WhlGndVelRDrvn_HS : 21|14@0+ (0.03125,0) [0|511.969] "km/h"  Instruments
 SG_ WhlGndVelRDrvnV_HS : 22|1@0+ (1,0) [0|1] ""  Instruments

BO_ 842 SCS_HSC1_FrP12: 8 Vector__XXX
 SG_ WhlGndVelLNonDrvn_HS : 5|14@0+ (0.03125,0) [0|511.969] "km/h"  Instruments
 SG_ WhlGndVelLNonDrvnV_HS : 6|1@0+ (1,0) [0|1] ""  Instruments
 SG_ WhlGndVelRNonDrvn_HS : 21|14@0+ (0.03125,0) [0|511.969] "km/h"  Instruments
 SG_ WhlGndVelRNonDrvnV_HS : 22|1@0+ (1,0) [0|1] ""  Instruments

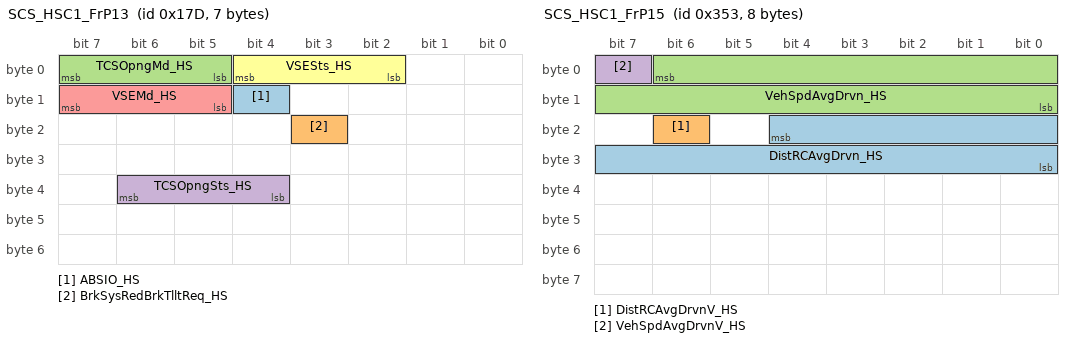
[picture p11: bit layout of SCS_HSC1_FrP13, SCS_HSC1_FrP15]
BO_ 381 SCS_HSC1_FrP13: 7 Vector__XXX
 SG_ ABSIO_HS : 12|1@0+ (1,0) [0|1] ""  Instruments
 SG_ BrkSysRedBrkTlltReq_HS : 19|1@0+ (1,0) [0|1] ""  Instruments
 SG_ TCSOpngMd_HS : 7|3@0+ (1,0) [0|7] ""  Instruments
 SG_ TCSOpngSts_HS : 38|3@0+ (1,0) [0|7] ""  Instruments
 SG_ VSEMd_HS : 15|3@0+ (1,0) [0|7] ""  Instruments
 SG_ VSESts_HS : 4|3@0+ (1,0) [0|7] ""  Instruments

BO_ 837 SCS_HSC1_FrP14: 8 Vector__XXX
 SG_ AutoHoldMsg_HS : 15|3@0+ (1,0) [0|7] ""  Instruments

BO_ 851 SCS_HSC1_FrP15: 8 Vector__XXX
 SG_ DistRCAvgDrvn_HS : 20|13@0+ (0.125,0) [0|1023.88] "m"  Instruments
 SG_ DistRCAvgDrvnV_HS : 22|1@0+ (1,0) [0|1] ""  Instruments
 SG_ VehSpdAvgDrvn_HS : 6|15@0+ (0.015625,0) [0|511.984] "km/h"  Instruments
 SG_ VehSpdAvgDrvnV_HS : 7|1@0+ (1,0) [0|1] ""  Instruments

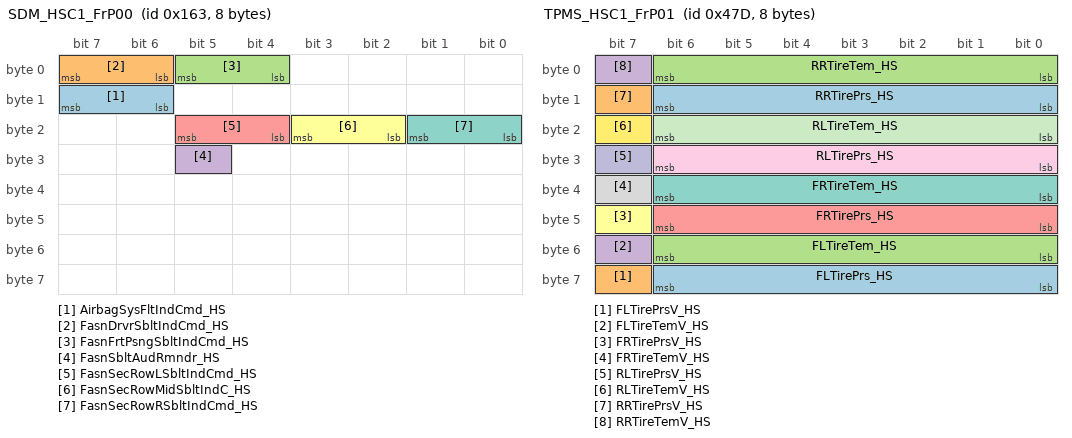
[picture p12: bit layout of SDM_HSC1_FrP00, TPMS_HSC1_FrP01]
BO_ 355 SDM_HSC1_FrP00: 8 Vector__XXX
 SG_ AirbagSysFltIndCmd_HS : 15|2@0+ (1,0) [0|3] ""  Instruments
 SG_ FasnDrvrSbltIndCmd_HS : 7|2@0+ (1,0) [0|3] ""  Instruments
 SG_ FasnFrtPsngSbltIndCmd_HS : 5|2@0+ (1,0) [0|3] ""  Instruments
 SG_ FasnSbltAudRmndr_HS : 29|1@0+ (1,0) [0|1] ""  Instruments
 SG_ FasnSecRowLSbltIndCmd_HS : 21|2@0+ (1,0) [0|3] ""  Instruments
 SG_ FasnSecRowMidSbltIndC_HS : 19|2@0+ (1,0) [0|3] ""  Instruments
 SG_ FasnSecRowRSbltIndCmd_HS : 17|2@0+ (1,0) [0|3] ""  Instruments

BO_ 1225 TCM_HSC1_FrP09: 7 Vector__XXX
 SG_ TrNonEmsnRltdMalfA_HS : 4|1@0+ (1,0) [0|1] ""  Instruments

BO_ 1072 TPMS_HSC1_FrP00: 1 Vector__XXX
 SG_ keep_network_TPMS_HS : 0|1@0+ (1,0) [0|1] ""  Instruments
 SG_ keep_network_TPMS_HS_UB : 1|1@0+ (1,0) [0|1] ""  Instruments

BO_ 1149 TPMS_HSC1_FrP01: 8 Vector__XXX
 SG_ FLTirePrs_HS : 62|7@0+ (4,0) [0|508] "Kpa"  Instruments
 SG_ FLTirePrsV_HS : 63|1@0+ (1,0) [0|1] ""  Instruments
 SG_ FLTireTem_HS : 54|7@0+ (2,-60) [-60|194] ""  Instruments
 SG_ FLTireTemV_HS : 55|1@0+ (1,0) [0|1] ""  Instruments
 SG_ FRTirePrs_HS : 46|7@0+ (4,0) [0|508] "Kpa"  Instruments
 SG_ FRTirePrsV_HS : 47|1@0+ (1,0) [0|1] ""  Instruments
 SG_ FRTireTem_HS : 38|7@0+ (2,-60) [-60|194] ""  Instruments
 SG_ FRTireTemV_HS : 39|1@0+ (1,0) [0|1] ""  Instruments
 SG_ RLTirePrs_HS : 30|7@0+ (4,0) [0|508] "Kpa"  Instruments
 SG_ RLTirePrsV_HS : 31|1@0+ (1,0) [0|1] ""  Instruments
 SG_ RLTireTem_HS : 22|7@0+ (2,-60) [-60|194] ""  Instruments
 SG_ RLTireTemV_HS : 23|1@0+ (1,0) [0|1] ""  Instruments
 SG_ RRTirePrs_HS : 14|7@0+ (4,0) [0|508] "Kpa"  Instruments
 SG_ RRTirePrsV_HS : 15|1@0+ (1,0) [0|1] ""  Instruments
 SG_ RRTireTem_HS : 6|7@0+ (2,-60) [-60|194] ""  Instruments
 SG_ RRTireTemV_HS : 7|1@0+ (1,0) [0|1] ""  Instruments

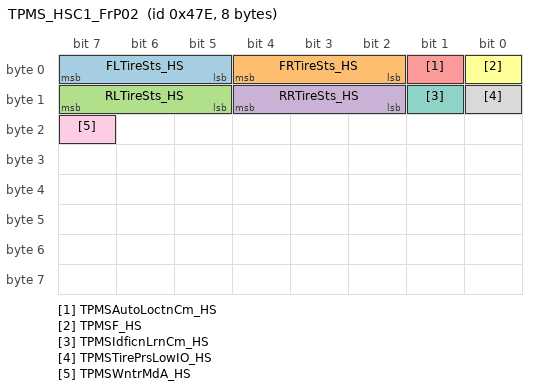
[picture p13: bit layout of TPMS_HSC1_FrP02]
BO_ 1150 TPMS_HSC1_FrP02: 8 Vector__XXX
 SG_ FLTireSts_HS : 7|3@0+ (1,0) [0|7] ""  Instruments
 SG_ FRTireSts_HS : 4|3@0+ (1,0) [0|7] ""  Instruments
 SG_ RLTireSts_HS : 15|3@0+ (1,0) [0|7] ""  Instruments
 SG_ RRTireSts_HS : 12|3@0+ (1,0) [0|7] ""  Instruments
 SG_ TPMSAutoLoctnCm_HS : 1|1@0+ (1,0) [0|1] ""  Instruments
 SG_ TPMSF_HS : 0|1@0+ (1,0) [0|1] ""  Instruments
 SG_ TPMSIdficnLrnCm_HS : 9|1@0+ (1,0) [0|1] ""  Instruments
 SG_ TPMSTirePrsLowIO_HS : 8|1@0+ (1,0) [0|1] ""  Instruments
 SG_ TPMSWntrMdA_HS : 23|1@0+ (1,0) [0|1] ""  Instruments

BO_ 1060 TPMS_HSC1_FrS00: 1 Vector__XXX
 SG_ wake_network_TPMS_HS : 0|1@0+ (1,0) [0|1] ""  Instruments
 SG_ wake_network_TPMS_HS_UB : 1|1@0+ (1,0) [0|1] ""  Instruments

CM_ SG_ 1522 keep_network_AC_HS "NM signal: the ATC/AC/ETC uses this signal when it wants to keep the network awake.
";
CM_ SG_ 1205 wake_network_AC_HS "NM signal: the ATC/AC/ETC uses this signal when it wants to wake-up the network";
CM_ SG_ 497 PwrMdMstrAccryA_H1_HS "Power Mode Master Accessory Terminal Status";
CM_ SG_ 497 PwrMdMstrRunCrkA_H1_HS "Power Mode Master Run Crank Terminal Status";
CM_ SG_ 497 SysOpnlMd_HS "System Operational Mode";
CM_ SG_ 497 SysPwrMdV_h1_HS "System Power Mode Validity ";
CM_ SG_ 497 SysPwrMd_h1_HS "System Power Mode";
CM_ SG_ 497 SysVol_HS "Battery Voltage";
CM_ SG_ 497 SysVolMd_HS "System Voltage Mode ";
CM_ SG_ 497 SysVolMdV_HS "System Voltage Mode Validity ";
CM_ SG_ 497 SysVolV_HS "Battery Voltage Validity";
CM_ SG_ 1344 VehOdoV_H1_HS "Vehicle Odometer Validity";
CM_ SG_ 1344 VehOdo_H1_HS "Vehicle Odometer";
CM_ SG_ 795 PwrMdMstrAccryWkupA_HS "Power Mode Master Accessory Wakeup Active";
CM_ SG_ 795 PwrMdMstrIgnA_HS "Power Mode Master Ignition Active";
CM_ SG_ 1055 network_mode "NM signal: this signal contains the intended mode of the network. This signal controls the frame mode used by the slave nodes";
CM_ SG_ 1055 signal_config_id "NM signal: this is the identification number of the signal configuration used. Read by the slave nodes to determine if they have the correct configuration or not";
CM_ SG_ 1139 VINBCM_H1_HS "VIN Code Record in BCM";
CM_ SG_ 1146 AmbtLghtLvl_H1_HS "Ambient Light Level
Indicate the Request from Auto Light Sensor";
CM_ SG_ 1146 LghtSwPosSts_H1_HS "Light Switch Position Status
Indicate the Posistion of  MLS ";
CM_ SG_ 1146 OdoSecy_HS "Odometer Secondary
Odo Backup in BCM";
CM_ SG_ 1146 SIAOdoSecy_HS "Service Interval Announcement Odometer Secondary";
CM_ SG_ 1130 BCMEmgcSp_HS "Body Control Module Emergency Stop";
CM_ SG_ 1130 BCMPwrMdHwdSta_HS "Body Control Module Power Mode Hardwired State";
CM_ SG_ 1130 BCMPwrMdHwdStaV_HS "Body Control Module Power Mode Hardwired State Validity";
CM_ SG_ 1130 BCMSSBA_HS "Body Control Module Start Stop Button Active
";
CM_ SG_ 1130 BCMSSBAV_HS "Body Control Module Start Stop Button Active Validity
";
CM_ SG_ 1130 BntOpenSts_H1_HS "Bonnet Open Status";
CM_ SG_ 1130 DipdBeamLghtOn_HS "Dipped Beam Light On
Indicate Dipped Beam Light was On for AFS";
CM_ SG_ 1130 DrvrDoorOpenSts_H1_HS "Driver Door Open Status";
CM_ SG_ 1130 FrtFogLghtOn_H1_HS "Front Fog Light On";
CM_ SG_ 1130 FrtPsngDoorOpenSts_H1_HS "Front Passenger Door Open Status";
CM_ SG_ 1130 LDircnIO_HS "Left Direction Indication On
Remind the Driver that Left Hand Direction Indicate Light was On";
CM_ SG_ 1130 LdspcOpenSts_H1_HS "Loadspace Open Status";
CM_ SG_ 1130 MainBeamLghtOn_H1_HS "Main Beam Light On
";
CM_ SG_ 1130 RDircnIO_HS "Right Direction Indication On
Remind the Driver that Right Hand Direction Indicate Light was On";
CM_ SG_ 1130 RRDoorOpenSts_HS "Rear Right Door Open Status";
CM_ SG_ 1130 RrFogLghtF_H1_HS "Rear Fog Light Failed";
CM_ SG_ 1130 RrFogLghtOn_H1_HS "Rear Fog Light On
";
CM_ SG_ 1130 VehLckngSta_H1_HS "Vehicle Locking State";
CM_ SG_ 1130 VehSideLghtSts_H1_HS "Vehicle Side Light Status";
CM_ SG_ 540 BCMGearShftParkNtrlESR_HS "Body Control Module Gear Shift Park Neutral Engine Starting Reminder
";
CM_ SG_ 540 BCMNoSmtKeyInVehRmndr_HS "Body Control Module No Smart Key In Vehicle Reminder";
CM_ SG_ 540 BCMNoSmtKeyPressBrkTRR_HS "Body Control Module No Smart Key Press Brake To Restart Reminder";
CM_ SG_ 540 BCMNoSmtKeyPressClToRR_HS "Body Control Module No Smart Key Press Clutch To Restart Reminder";
CM_ SG_ 540 BCMPressBrkRmndr_HS "Body Control Module Press Brake Reminder";
CM_ SG_ 540 BCMPressClRmndr_HS "Body Control Module Press Clutch Reminder";
CM_ SG_ 540 BCMPutSmtKeyToBkupPosR_HS "Body Control Module Put Smart Key Into Backup Position Reminder";
CM_ SG_ 540 BCMRunCrkF_HS "Body Control Module Run Crank Failed
";
CM_ SG_ 540 BCMShftParkRmndr_HS "Body Control Module Shift Park Reminder";
CM_ SG_ 540 BCMSSBFltSts_HS "Body Control Module Start Stop Button Fault Status
";
CM_ SG_ 540 BCMTakeSmtKeyOutOfSR_HS "Body Control Module Take Smart Key Out Of Slot Reminder";
CM_ SG_ 540 DayTimeRunningLghtF_HS "Day Time Running Light Failed";
CM_ SG_ 540 DrvrWndOpenRmndr_HS "Driver Window Open Reminder
";
CM_ SG_ 540 FrtSideLghtF_HS "Front Side Light Failed
";
CM_ SG_ 540 LBrkLghtF_HS "Left Brake Light Failed";
CM_ SG_ 540 LDipdBeamLghtF_HS "Left Dipped Beam Light Failed";
CM_ SG_ 540 LDircnIndLghtF_H1_HS "Left Direction Indication Light Failed";
CM_ SG_ 540 PEPSAntFlt_HS "Passive Entry Passive Start Antenna Fault";
CM_ SG_ 540 RBrkLghtF_HS "Right Brake Light Failed";
CM_ SG_ 540 RDipdBeamLghtF_HS "Right Dipped Beam Light Failed";
CM_ SG_ 540 RDircnIndLghtF_H1_HS "Right Direction Indication Light Failed";
CM_ SG_ 540 RevsLghtF_H1_HS "Reverse Light Failed";
CM_ SG_ 540 RrSideLghtF_HS "Rear Side Light Failed
";
CM_ SG_ 540 ScurtAlrmSts_HS "Security Alarm Status";
CM_ SG_ 540 ScurtKeyBatLow_HS "Security Key Battery Low";
CM_ SG_ 540 ScurtKeyInvd_HS "Security Key Invalid";
CM_ SG_ 540 ShifterLckRlseBrkReqA_HS "Shifter Lock Release Brake Request Active";
CM_ SG_ 540 SrfOpenRmndr_HS "Sunroof Open Reminder";
CM_ SG_ 540 SSBEnOffRmndr_HS "Start Stop Button Engine OFF  Reminder";
CM_ SG_ 540 TakeKeyOutRmndr_HS "Take Key Out Reminder";
CM_ SG_ 541 BCMSyncSmtKeyRmndr_HS "Body Control Module Synchronize Smart Key Reminder";
CM_ SG_ 541 DrvrPWLInitnRmndr_HS "Driver Power Window Lifter Initialization Reminder,Remind the Driver to Initialize Driver Power Window Lifter";
CM_ SG_ 541 SrfInitnRmndr_HS "Sunroof Initialization Reminder";
CM_ SG_ 793 BatVol_HS "Battery voltage sampled by PMDC";
CM_ SG_ 814 BatAgngSta_HS "Battery Aging State
";
CM_ SG_ 814 GenrSta_HS "state of generator";
CM_ SG_ 1303 BatSOC_HS "Battery State Of Charge";
CM_ SG_ 1303 VehLdShedLvl_H1_HS "Vehicle Load Shed Level
power risk for load sheding";
CM_ SG_ 845 EmgcCallFlrSts_HS "Emergency Call Failure Status";
CM_ SG_ 2015 DiagnosticFuncAddrReq "Diagnostic functional address request";
CM_ SG_ 1888 DiagnosticReqIPK "Diagnostic request to IPK";
CM_ SG_ 1896 DiagnosticRespIPK "Diagnostic response from IPK";
CM_ SG_ 1546 DiagnosticReqVKR "test for ZS12 TFT IPK";
CM_ SG_ 1547 DiagnosticRespVKR "test for ZS12 TFT IPK";
CM_ SG_ 201 CCA_HS "Cruise Control Active";
CM_ SG_ 201 CCEnbd_HS "Cruise Control Enabled";
CM_ SG_ 201 En12VoltStrMotCmddOn_HS "Engine 12 Volt Starter Motor Commanded On";
CM_ SG_ 201 EnRunA_HS "Engine Run Active";
CM_ SG_ 201 EnSpd_HS "Engine Speed";
CM_ SG_ 201 EnSpdSts_HS "Engine Speed Status";
CM_ SG_ 404 DrvrShftCtrlTrgtGear_HS "Driver Shift Control Target Gear";
CM_ SG_ 404 TrShftLvrPos_HS "Transmission Shift Lever Position

For DCT/AT transmission :
$0=Between Ranges
$1=Park Range
$2=Reverse Range
$3=Neutral Range
$4=Forward Range A
$5=Forward Range B
$6=Forward Range C
$7=Forward Range D
$8=Forward Range E
$9=Forward Range F
$A=Forward Range G
$B=Forward Range H
$F=Lever Position Unknown

For Manual Transmission: only below status are used
$2=Reverse Range
$3=Neutral Range (Validity on MT vehicles is only protected for Neutral range)
$F=Lever Position Unknown";
CM_ SG_ 404 TrShftLvrPosV_HS "Transmission Shift Lever Position Validity";
CM_ SG_ 404 TrShftPtrnASts_HS "Transmission Shift Pattern Active Status";
CM_ SG_ 404 TrTapUpTapDwnMdSts_HS "Transmission Tap Up Tap Down Mode Status";
CM_ SG_ 479 EnASSSta_HS "Engine Auto Stop Start State";
CM_ SG_ 707 EcoDrvngAIO_HS "Economy Driving Active Indication On";
CM_ SG_ 707 EcoDrvngDspStsGearSIS_HS "Economy Driving Display Status Gear Shift Indication Status";
CM_ SG_ 707 EcoDrvngDspStsRcmndFG_HS "Economy Driving Display Status Recommended Forward Gear";
CM_ SG_ 707 ECODrvngSpdRutA_HS "Economic Driving  Speed Route Active";
CM_ SG_ 945 ASSInhBtnLampOn_HS "Auto Stop Start Inhibit Button Lamp On
";
CM_ SG_ 945 ASSInhIO_HS "Auto Stop Start Inhibit Indication On

";
CM_ SG_ 945 ASSStsLampOn_HS "Auto Stop Start Status Lamp On";
CM_ SG_ 945 ASSWrnngLampOn_HS "Auto Stop Start Warning Lamp On
";
CM_ SG_ 945 CCFltPrst_HS "Cruise Control Fault Present";
CM_ SG_ 945 ECMClsDoorToAutoStR_HS "Engine Control Module Close Door To Auto Start Reminder";
CM_ SG_ 945 ECMFasnSbltToAutoStR_HS "Engine Control Module Fasten Seatbelt To Auto Start Reminder";
CM_ SG_ 945 ECMPressClBrkRmndr_HS "Engine Control Module Press Clutch Brake Reminder";
CM_ SG_ 945 ECMShftNtrlToAutoStR_HS "Engine Control Module Shift Neutral To Auto Start Reminder";
CM_ SG_ 977 CrusAndSpdLmtrDrvrSS_HS "Cruise and Speed Limiter Driver Selected Speed";
CM_ SG_ 977 EnEmsnRltdMalfA_HS "Engine Emissions Related Malfunction Active";
CM_ SG_ 977 EnEmsnRltdMalfIndReq_HS "Engine Emissions Related Malfunction Indication Request";
CM_ SG_ 977 EnGPFLampOnSts_HS "Engine GPF Lamp On Status";
CM_ SG_ 977 EnNonEmsnRltdMalfA_HS "Engine Non Emissions Related Malfunction Active";
CM_ SG_ 977 FuelCsump_HS "Fuel Consumption";
CM_ SG_ 1217 EnClntTem_HS "Engine Coolant Temperature";
CM_ SG_ 1217 EnClntTemV_HS "Engine Coolant Temperature Validity";
CM_ SG_ 1233 EnOilPrsLowIO_HS "Engine Oil Pressure Low Indication On";
CM_ SG_ 251 SpdAstSysStsECM_HS "Speed Assist System Status Engine Control Module
";
CM_ SG_ 251 SpdAstSysTrgtSpd_HS "Speed Assist System Target Speed
";
CM_ SG_ 560 EPBSysAudWrnngReq_HS "Electric Park Brake System Audible Warning Request";
CM_ SG_ 560 EPBSysDspMsgReq_HS "Electric Park Brake System Display Message Request";
CM_ SG_ 560 EPBSysStsIndReq_HS "Electric Park Brake System Status Indication Request";
CM_ SG_ 560 EPBSysWrnngIndReq_HS "Electric Park Brake System Warning Indication Request";
CM_ SG_ 328 EPSFlrSts_HS "'

Electric Power Steering Failure Status'
";
CM_ SG_ 1071 keep_network_ESCL_HS "NM signal: the ESCL uses this signal when it wants to keep the network awake.";
CM_ SG_ 1127 ESCLFlrIndCmd_HS "Electronic Steering Column Lock Failure Indication Command";
CM_ SG_ 1059 wake_network_ESCL_HS "NM signal: the ESCL uses this signal when it wants to wake-up the network";
CM_ SG_ 1104 keep_network_FICM_HS "NM signal: the FICM/ICE uses this signal when it wants to keep the network awake.";
CM_ SG_ 875 ChmA_HS "Chime Active";
CM_ SG_ 875 FICMTemUntAdj_HS "Front Infotainment Control Module Temperature Units Adjust";
CM_ SG_ 875 LanggSetngAdj_HS "Language Setting Adjustment
Language Setting Adjustment from infotainment";
CM_ SG_ 875 LanggSetngAdjReqA_HS "Language Setting Adjustment Request Active";
CM_ SG_ 886 FICMDistUnitAdjtReqA_HS "Front Infotainment Control Module Distance Unit Adjust Request Active";
CM_ SG_ 1291 CalendarAdjReqA_HS "Calendar Adjustment Request Active
Calendar Adjustment Request from infotainment";
CM_ SG_ 1291 CalendarDayAdj_HS "Calendar Day Adjustment
Calendar Day Adjustment information from infotainment";
CM_ SG_ 1291 CalendarMonthAdj_HS "Calendar Month Adjustment
Calendar Month Adjustment information from infotainment";
CM_ SG_ 1291 CalendarYearAdj_HS "Calendar Year Adjustment
Calendar Year Adjustment information from infotainment";
CM_ SG_ 1291 HourOfDayAdj_HS "Hour Of Day Adjustment
Hour of Day Adjustment from infotainment";
CM_ SG_ 1291 MinuteOfHourAdj_HS "Minute Of Hour Adjustment
Minute of Hour Adjustment from infotainment";
CM_ SG_ 1291 SecsOfMinuteAdj_HS "Seconds Of Minute Adjustment
Seconds of Minute Adjustment from infotainment";
CM_ SG_ 1291 TimeAdjReqA_HS "Time Adjustment Request Active
Time Adjustment Request from infotainment";
CM_ SG_ 1291 TimeDspFmtAdj_HS "Time Display Format Adjustment
Time Display Format Adjustment from infotainment";
CM_ SG_ 871 FICMDistUntAdj_HS "Front Infotainment Control Module Distance Units Adjust";
CM_ SG_ 871 FICMFuelCsumpUntAdj_HS "Front Infotainment Control Module Fuel Consumption Units Adjust";
CM_ SG_ 871 FICMFuelCsumpUntAdjARA_HS "Ficm Fuel Consumption Units Adjust Request";
CM_ SG_ 871 FICMOverSpdFnCrntSts_HS "Front Infotainment Control Module Over Speed Function Current Status
";
CM_ SG_ 871 FICMOvrSpdThrshldAdj_HS "Front Infotainment Control Module Over Speed Threshold Adjust";
CM_ SG_ 871 FICMOvrSpdThrshldAdjtRA_HS "Ficm Over Speed Threshold Adjust Request";
CM_ SG_ 871 FICMTemUntAdjtReqA_HS "Ficm Temperature Units Adjust Request";
CM_ SG_ 871 FICMTyrePressureUntAdj_HS "Ficm Tyre Pressure Units Adjust";
CM_ SG_ 871 FICMTyrePressureUntAdjtReqA_HS "Ficm Tyre Pressure Units Adjust Request";
CM_ SG_ 871 FICMVehMntnceSts_HS "Front Infotainment Control Module Vehicle Maintenance Status
";
CM_ SG_ 871 MusSrcMd_HS "Music Source Mode";
CM_ SG_ 871 RdoFrqcVal_HS "Radio Frequency Value";
CM_ SG_ 893 NavDircn_HS "Navigation Direction";
CM_ SG_ 893 NavDist_HS "Navigation Distance";
CM_ SG_ 893 NavDistUnit_HS "Navigation Distance Unit";
CM_ SG_ 1095 wake_network_FICM_HS "NM signal: the FICM/ICE uses this signal when it wants to wake-up the network";
CM_ SG_ 217 ASSInhBtnA_HS "Auto Stop Start Inhibit Button Active
";
CM_ SG_ 498 SysBPM_HS "System Backup Power Mode";
CM_ SG_ 498 SysBPMEnbd_HS "System Backup Power Mode Enabled";
CM_ SG_ 499 PfTrTapUpDwnEnbSwSta_HS "Platform Transmission Tap Up/Down Enable Switch State";
CM_ SG_ 499 PfTrTapUpDwnSecySwSta_HS "Platform Transmission Tap Up/Down Secondary Switch State";
CM_ SG_ 499 PfTrTapUpDwnSwSta_HS "Platform Transmission Tap Up/Down Switch State";
CM_ SG_ 499 PfTrTapUpDwnSwStsAlvRC_HS "Platform Transmission Tap Up/Down Switch Status Alive Rolling Count";
CM_ SG_ 499 TrPfShftPtrnSw1A_HS "Transmission Platform Shift Pattern Switch 1 Active";
CM_ SG_ 499 TrPfShftPtrnSw4A_HS "Transmission Platform Shift Pattern Switch 4 Active";
CM_ SG_ 499 TrPfShftPtrnSwAlvRC_HS "Transmission Platform Shift Pattern Switch Alive Rolling Count";
CM_ SG_ 481 CCSwStsAlvRC_HS "Cruise Control Switch Status Alive Rolling Count";
CM_ SG_ 481 CCSwStsCanclSwA_HS "Cruise Control Switch Status : Cancel Switch Active";
CM_ SG_ 481 CCSwStsDisDecSwA_HS "Cruise Control Switch Status Distance Decrease Switch Active";
CM_ SG_ 481 CCSwStsDistIncSwA_HS "Cruise Control Switch Status Distance Increase Switch Active";
CM_ SG_ 481 CCSwStsOnSwA_HS "Cruise Control Switch Status : On Switch Active";
CM_ SG_ 481 CCSwStsPV_HS "Cruise Control Switch Status Protection Value";
CM_ SG_ 481 CCSwStsRsmSwA_HS "Cruise Control Switch Status : Resume Switch Active";
CM_ SG_ 481 CCSwStsSetSwA_HS "Cruise Control Switch Status : Set Switch Active";
CM_ SG_ 481 CCSwStsSpdDecSwA_HS "Cruise Control Switch Status : Speed Decrease Switch Active";
CM_ SG_ 481 CCSwStsSpdIncSwA_HS "Cruise Control Switch Status : Speed Increase Switch Active";
CM_ SG_ 481 CCSwStsSwDataIntgty_HS "Cruise Control Switch Status Switch Data Integrity";
CM_ SG_ 1523 keep_network_IPK_HS "NM signal: the IPK uses this signal when it wants to keep the network awake.";
CM_ SG_ 1142 VINClstr_HS "Vehicle Identifier Number Cluster
the last 8 btyes' of VIN.";
CM_ SG_ 1046 AirbagWrnngIndF_HS "Airbag Warning Indication Failed
send out the status of Airbag warning lamp";
CM_ SG_ 1046 Clstr10KmTick_HS "Cluster 10 Kilometer Tick
when IPK'VIN code does match with other module, IPK will send '1' status out.";
CM_ SG_ 1046 DspMeasSys_HS "Display Measurement System";
CM_ SG_ 1046 FuelLvlPcnt_HS "Fuel Level Percent
percent of cyrrent tank level divide 'Fuel Total Capacity'.";
CM_ SG_ 1046 FuelLvlPcntV_HS "Fuel Level Percent Validity
when fuel sensor resistance is out of range, the signal value is set to 1 otherwise set to 0.";
CM_ SG_ 1046 FuelTotCapct_HS "Fuel Total Capacity
fuel tank max capacity, which can be detected by fuel sensor.";
CM_ SG_ 1046 SIADatePriy_HS "Service Interval Announcement Date Primary
the date of last do SIA operation.

0x xx xx xx=(Year, Month, Date).

MSB:year,
LSB:day";
CM_ SG_ 858 AvgFuelCsump_HS "Average Fuel Consumption";
CM_ SG_ 858 AvgFuelCsumpV_HS "Average Fuel Consumption Validity";
CM_ SG_ 858 ChmCmdSndCndcPrd_HS "Sound  Characteristics
Chime Command Sound Cadence Period ";
CM_ SG_ 858 ChmCmdSndDutyCyc_HS "Sound  Characteristics
Chime Command Sound Duty Cycle";
CM_ SG_ 858 ChmCmdSndLoctnFL_HS "sound location
Chime Command Sound Location Front Left";
CM_ SG_ 858 ChmCmdSndLoctnFR_HS "sound location
Chime Command Sound Location Front Right";
CM_ SG_ 858 ChmCmdSndLoctnRL_HS "sound location
Chime Command Sound Location Rear Left";
CM_ SG_ 858 ChmCmdSndLoctnRR_HS "sound location
Chime Command Sound Location Rear Right";
CM_ SG_ 858 ChmCmdSndTone_HS "Sound  Characteristics
Chime Command Sound Tone";
CM_ SG_ 858 ClstrDspdVehSpd_HS "Cluster Displayed Vehicle Speed";
CM_ SG_ 858 IPCAccryA_HS "Instrument Panel Cluster Start Accessory Active";
CM_ SG_ 858 IPCRunCrkA_HS "Instrument Panel Cluster Run Crank Active";
CM_ SG_ 858 IPCRunCrkF_HS "Instrument Panel Cluster Run Crank Failed";
CM_ SG_ 858 IPCSSBA_HS "Instrument Panel Cluster Start Stop Button Active";
CM_ SG_ 858 IPCSSBAV_HS "Instrument Panel Cluster Start Stop Button Active Validity";
CM_ SG_ 858 IPCSSBFltSts_HS "Instrument Panel Cluster Start Stop Button Fault Status";
CM_ SG_ 858 LanggSetng_HS "Language Setting";
CM_ SG_ 1134 OdoPriy_HS "Odometer Primary
Odometer value";
CM_ SG_ 1134 SIAOdoPriy_HS "Service Interval Announcement Odometer Primary
the odometer value of last do SIA operation.";
CM_ SG_ 1345 CalendarDay_HS "current day info.";
CM_ SG_ 1345 CalendarMonth_HS "current month info.";
CM_ SG_ 1345 CalendarYear_HS "current year info";
CM_ SG_ 1345 HourOfDay_HS "Hour Of Day.
current Hour info.";
CM_ SG_ 1345 MinuteOfHour_HS "Minute Of Hour.
current Minute info.";
CM_ SG_ 1345 SecsOfMinute_HS "Seconds Of Minute
current Second info.";
CM_ SG_ 1345 TimeDspFmt_HS "Time Display Format
current Time format.";
CM_ SG_ 1123 IPCEcoDrvngSwA_HS "Instrument Cluster Economy Driving Switch Active
";
CM_ SG_ 874 ClstrDistUnt_HS "Cluster Distance Units";
CM_ SG_ 874 ClstrFuelCsumpUnt_HS "Cluster Fuel Consumption Units";
CM_ SG_ 874 ClstrOverSpdFnHstrSts_HS "Cluster Over Speed Function History Status
";
CM_ SG_ 874 ClstrOvrSpdThrshld_HS "Cluster Over Speed Threshold
";
CM_ SG_ 874 ClstrTemUnt_HS "Cluster Temperature Units
";
CM_ SG_ 874 ClstrTyrePressureUnt_HS "Cluster Tyre Pressure Units";
CM_ SG_ 874 RmnDrvngDist_HS "Remain Driving Distance";
CM_ SG_ 1047 ClstrDspdABSWrnng_HS "Cluster Displayed Antilock Brake System Warning";
CM_ SG_ 1047 ClstrDspdAirbagWrnng_HS "Cluster Displayed Airbag Warning";
CM_ SG_ 1047 ClstrDspdAltrWrnng_HS "Cluster Displayed Alternator Warning
";
CM_ SG_ 1047 ClstrDspdASpdLmtrWrnng_HS "Cluster Displayed Active Speed Limiter Warning";
CM_ SG_ 1047 ClstrDspdAutoholdWrnng_HS "Cluster Displayed Autohold Warning
";
CM_ SG_ 1047 ClstrDspdBatRplmntRqdW_HS "Cluster Displayed Battery Replacement Required Warning
";
CM_ SG_ 1047 ClstrDspdBrkSysWrnng_HS "Cluster Displayed Brake System Warning";
CM_ SG_ 1047 ClstrDspdCCWrnng_HS "Cluster Displayed Cruise Control Warning";
CM_ SG_ 1047 ClstrDspdClntTemWrnng_HS "Cluster Displayed Coolant Temperature Warning";
CM_ SG_ 1047 ClstrDspdClSwWrnng_HS "Cluster Displayed Clutch Switch Warning
";
CM_ SG_ 1047 ClstrDspdDayTimeRLW_HS "Cluster Displayed Day Time Running Lamp Warning
";
CM_ SG_ 1047 ClstrDspdEleccParkngBW_HS "Cluster Displayed Electronic Parking Brake Warning
";
CM_ SG_ 1047 ClstrDspdEnDrvByWireW_HS "Cluster Displayed Engine Drive By Wire Warning";
CM_ SG_ 1047 ClstrDspdEPSWrnng_HS "Cluster Displayed Electric Power Steering Warning";
CM_ SG_ 1047 ClstrDspdFuelLvlSgmt_HS "Cluster Displayed Fuel Level Segment";
CM_ SG_ 1047 ClstrDspdFuelSnsrWrnng_HS "Cluster Displayed Fuel Sensor Warning";
CM_ SG_ 1047 ClstrDspdFuelSts_HS "Cluster Displayed Fuel Status";
CM_ SG_ 1047 ClstrDspdHDCWrnng_HS "Cluster Displayed Hill Descent Control Warning
";
CM_ SG_ 1047 ClstrDspdIgnRelayWrnng_HS "
";
CM_ SG_ 1047 ClstrDspdInfoMsk_HS "Cluster Displayed Information Mask";
CM_ SG_ 1047 ClstrDspdInvdKeyWrnng_HS "Cluster Displayed Invalid Key Warning";
CM_ SG_ 1047 ClstrDspdLBrkLghtWrnng_HS "Cluster Displayed Left Brake Light Warning
";
CM_ SG_ 1047 ClstrDspdLDipdBeamLW_HS "Cluster Displayed Left Dipped Beam Light Warning
";
CM_ SG_ 1047 ClstrDspdLDircnIndLW_HS "Cluster Displayed Left Direction Indication Light Warning
";
CM_ SG_ 1047 ClstrDspdLSideLghtW_HS "Cluster Displayed Left Side Light Warning
";
CM_ SG_ 1047 ClstrDspdMalfIndrLghtW_HS "Cluster Displayed Malfunction Indicator Light Warning";
CM_ SG_ 1047 ClstrDspdOilPrsLowW_HS "Cluster Displayed Oil Pressure Low Warning";
CM_ SG_ 1047 ClstrDspdPDCWrnng_HS "Cluster Displayed Park Distance Control Warning
";
CM_ SG_ 1047 ClstrDspdRDipdBeamLW_HS "
";
CM_ SG_ 1047 ClstrDspdRrFogLghtW_HS "
";
CM_ SG_ 1047 ClstrDspdRSideLghtW_HS "
";
CM_ SG_ 1047 ClstrDspdSASUncalWrnng_HS "Cluster Displayed Steering Angle Sensor Uncalibartion Warning";
CM_ SG_ 1047 ClstrDspdSASWrnng_HS "Cluster Displayed Steering Angle Sensor Warning";
CM_ SG_ 1047 ClstrDspdSCSWrnng_HS "Cluster Displayed Stability Control System Warning";
CM_ SG_ 1047 ClstrDspdScurtKeyBatLW_HS "Cluster Displayed Security Key Battery Low Warning";
CM_ SG_ 1047 ClstrDspdSpStBtnWrnng_HS "
";
CM_ SG_ 1047 ClstrDspdSpStWrnng_HS "Cluster Displayed Stop Start Warning";
CM_ SG_ 1047 ClstrDspdTCSWrnng_HS "Cluster Displayed Traction Control System Warning";
CM_ SG_ 1047 ClstrDspdTrWrnng_HS "Cluster Displayed Transmission Warning";
CM_ SG_ 1047 ClstrDspdTyrePrsSts_HS "Cluster Displayed Tyre Pressure Status";
CM_ SG_ 1144 ClstrDspdFLTirePrs_HS "Cluster Displayed Front Left Tire Pressure";
CM_ SG_ 1144 ClstrDspdFLTireSts_HS "Cluster Displayed Front Left Tire Status";
CM_ SG_ 1144 ClstrDspdFRTirePrs_HS "Cluster Displayed Front Right Tire Pressure";
CM_ SG_ 1144 ClstrDspdFRTireSts_HS "Cluster Displayed Front Right Tire Status";
CM_ SG_ 1144 ClstrDspdRLTirePrs_HS "Cluster Displayed Rear Left Tire Pressure";
CM_ SG_ 1144 ClstrDspdRLTireSts_HS "Cluster Displayed Rear Left Tire Status";
CM_ SG_ 1144 ClstrDspdRRTirePrs_HS "Cluster Displayed Rear Right Tire Pressure";
CM_ SG_ 1144 ClstrDspdRRTireSts_HS "Cluster Displayed Rear Right Tire Status";
CM_ SG_ 1144 StabCtrlDsblSwA_HS "Stability Control Disable Switch Active";
CM_ SG_ 1531 wake_network_IPK_HS "NM signal: the IPK uses this signal when it wants to wake-up the network";
CM_ SG_ 1087 sm_network_mode_h1 "NM signal published by Second Master node: this signal contains the intended mode of the network. This signal controls the frame mode used by the slave nodes.";
CM_ SG_ 1087 sm_signal_config_id_h1 "NM signal published by second master node: this is the identification number of the signal configuration used. Read by the slave nodes to determine if they have the correct configuration or not";
CM_ SG_ 573 FLObsRng_HS "Front Left Obstacle Range";
CM_ SG_ 573 FRObsRng_HS "Front Right Obstacle Range";
CM_ SG_ 573 FrtMidLObsRng_HS "Front Middle Left Obstacle Range";
CM_ SG_ 573 FrtMidRObsRng_HS "Front Middle Right Obstacle Range";
CM_ SG_ 573 FrtObsDist_HS "Front Obstacle Distance
";
CM_ SG_ 573 PDCCofignSts_HS "Park Distance Control Configuration Status";
CM_ SG_ 573 PDCSysSts_HS "Park Distance Control System Status";
CM_ SG_ 573 RLObsRng_HS "Rear Left Obstacle Range";
CM_ SG_ 573 RrMidLObsRng_HS "Rear Middle Left Obstacle Range";
CM_ SG_ 573 RrMidRObsRng_HS "Rear Middle Right Obstacle Range";
CM_ SG_ 573 RrObsDist_HS "Rear Obstacle Distance

";
CM_ SG_ 573 RRObsRng_HS "Rear Right Obstacle Range";
CM_ SG_ 485 StrgWhlAngSnsrCalSts_HS "Steering Wheel Angle Sensor Calibration Status";
CM_ SG_ 485 StrgWhlAngSnsrFlt_HS "Steering Wheel Angle Sensor Fault";
CM_ SG_ 455 AutoHoldSysSts_HS "Auto Hold System Status";
CM_ SG_ 562 HDCSysSts_HS "Hill Descent Control System Status";
CM_ SG_ 532 BrkFludLvlLow_HS "Brake Fluid Level Low";
CM_ SG_ 532 BrkFludLvlLowV_HS "Brake Fluid Level Low Validity";
CM_ SG_ 840 WhlGndVelLDrvn_HS "Wheel Ground Velocity Left Driven";
CM_ SG_ 840 WhlGndVelLDrvnV_HS "Wheel Ground Velocity Left Driven Validity";
CM_ SG_ 840 WhlGndVelRDrvn_HS "Wheel Ground Velocity Right Driven";
CM_ SG_ 840 WhlGndVelRDrvnV_HS "Wheel Ground Velocity Right Driven Validity";
CM_ SG_ 842 WhlGndVelLNonDrvn_HS "Wheel Ground Velocity Left Non Driven";
CM_ SG_ 842 WhlGndVelLNonDrvnV_HS "Wheel Ground Velocity Left Non Driven Validity";
CM_ SG_ 842 WhlGndVelRNonDrvn_HS "Wheel Ground Velocity Right Non Driven";
CM_ SG_ 842 WhlGndVelRNonDrvnV_HS "Wheel Ground Velocity Right  Non Driven Validity";
CM_ SG_ 381 ABSIO_HS "Antilock Brake System Indication On";
CM_ SG_ 381 BrkSysRedBrkTlltReq_HS "Brake System Red Brake Telltale Request";
CM_ SG_ 381 TCSOpngMd_HS "Traction Control System Operating Mode";
CM_ SG_ 381 TCSOpngSts_HS "Traction Control System Operating Status";
CM_ SG_ 381 VSEMd_HS "Vehicle Stability Enhancement Mode";
CM_ SG_ 381 VSESts_HS "Vehicle Stability Enhancement Status";
CM_ SG_ 837 AutoHoldMsg_HS "Autohold Message";
CM_ SG_ 851 DistRCAvgDrvn_HS "Distance Rolling Count Average Driven";
CM_ SG_ 851 DistRCAvgDrvnV_HS "Distance Rolling Count Average Driven Validity";
CM_ SG_ 851 VehSpdAvgDrvn_HS "Vehicle Speed Average Driven";
CM_ SG_ 851 VehSpdAvgDrvnV_HS "Vehicle Speed Average Driven Validity";
CM_ SG_ 355 AirbagSysFltIndCmd_HS "Airbag System Fault Indication Command";
CM_ SG_ 355 FasnDrvrSbltIndCmd_HS "Fasten Driver Seatbelt Indication Command";
CM_ SG_ 355 FasnFrtPsngSbltIndCmd_HS "Fasten Front Passenger Seatbelt Indication Command";
CM_ SG_ 355 FasnSbltAudRmndr_HS "Fasten Seatbelt Audible Reminder
";
CM_ SG_ 355 FasnSecRowLSbltIndCmd_HS "Fasten Second Row Left Seatbelt Indication Command
";
CM_ SG_ 355 FasnSecRowMidSbltIndC_HS "Fasten Second Row Middle Seatbelt Indication Command
";
CM_ SG_ 355 FasnSecRowRSbltIndCmd_HS "Fasten Second Row Right Seatbelt Indication Command
";
CM_ SG_ 1225 TrNonEmsnRltdMalfA_HS "Transmission Non Emissions Related Malfunction Active";
CM_ SG_ 1072 keep_network_TPMS_HS "NM signal: the TPMS uses this signal when it wants to keep the network awake.
";
CM_ SG_ 1149 FLTirePrs_HS "Front Left Tire Pressure";
CM_ SG_ 1149 FLTirePrsV_HS "Front Left Tire Pressure Validity";
CM_ SG_ 1149 FLTireTem_HS "Front Left Tire Temperature";
CM_ SG_ 1149 FLTireTemV_HS "Front Left Tire Temperature Validity";
CM_ SG_ 1149 FRTirePrs_HS "Front Right Tire Pressure";
CM_ SG_ 1149 FRTirePrsV_HS "Front Right Tire Pressure Validity";
CM_ SG_ 1149 FRTireTem_HS "Front Right Tire Temperature";
CM_ SG_ 1149 FRTireTemV_HS "Front Right Tire Temperature Validity";
CM_ SG_ 1149 RLTirePrs_HS "Rear Left Tire Pressure";
CM_ SG_ 1149 RLTirePrsV_HS "Rear Left Tire Pressure Validity";
CM_ SG_ 1149 RLTireTem_HS "Rear Left Tire Temperature";
CM_ SG_ 1149 RLTireTemV_HS "Rear Left Tire Temperature Validity";
CM_ SG_ 1149 RRTirePrs_HS "Rear Right Tire Pressure";
CM_ SG_ 1149 RRTirePrsV_HS "Rear Right Tire Pressure Validity";
CM_ SG_ 1149 RRTireTem_HS "Rear Right Tire Temperature";
CM_ SG_ 1149 RRTireTemV_HS "Rear Right Tire Temperature Validity";
CM_ SG_ 1150 FLTireSts_HS "Front Left Tire Status";
CM_ SG_ 1150 FRTireSts_HS "Front Right Tire Status";
CM_ SG_ 1150 RLTireSts_HS "Rear Left Tire Status";
CM_ SG_ 1150 RRTireSts_HS "Rear Right Tire Status";
CM_ SG_ 1150 TPMSAutoLoctnCm_HS "Tire Pressure Monitor System Auto Location Complete";
CM_ SG_ 1150 TPMSF_HS "Tire Pressure Monitor System Failed";
CM_ SG_ 1150 TPMSIdficnLrnCm_HS "Tire Pressure Monitor System Identification Learn Complete";
CM_ SG_ 1150 TPMSTirePrsLowIO_HS "Tire Pressure Monitor System Tire Pressure Low Indication On";
CM_ SG_ 1150 TPMSWntrMdA_HS "Tire Pressure Monitor System Winter Mode Active";
CM_ SG_ 1060 wake_network_TPMS_HS "NM signal: the TPMS uses this signal when it wants to wake-up the network";
BA_DEF_  "BusType" STRING ;
BA_DEF_ SG_  "GenSigLongName" STRING ;
BA_DEF_ SG_  "GenSigStartValue" INT -9.22337203685478E+018 1.84467440737096E+019;
BA_DEF_ BO_  "GenMsgDelayTime" FLOAT 0 300000;
BA_DEF_ BO_  "GenMsgCycleTime" FLOAT 0 300000;
BA_DEF_ BO_  "GenMsgSendType" ENUM  "cyclic","spontaneous","cyclicIfActive","spontaneousWithDelay","immediate";
BA_DEF_DEF_  "BusType" "";
BA_DEF_DEF_  "GenSigLongName" "";
BA_DEF_DEF_  "GenSigStartValue" 0;
BA_DEF_DEF_  "GenMsgDelayTime" 0;
BA_DEF_DEF_  "GenMsgCycleTime" 0;
BA_DEF_DEF_  "GenMsgSendType" "";
BA_ "BusType" "CAN";
BA_ "GenMsgCycleTime" BO_ 1522 100;
BA_ "GenMsgSendType" BO_ 1522 0;
BA_ "GenMsgSendType" BO_ 1205 1;
BA_ "GenMsgCycleTime" BO_ 497 20;
BA_ "GenMsgSendType" BO_ 497 0;
BA_ "GenMsgCycleTime" BO_ 1344 1000;
BA_ "GenMsgSendType" BO_ 1344 0;
BA_ "GenMsgCycleTime" BO_ 795 100;
BA_ "GenMsgSendType" BO_ 795 0;
BA_ "GenMsgSendType" BO_ 1055 4;
BA_ "GenMsgCycleTime" BO_ 1139 200;
BA_ "GenMsgSendType" BO_ 1139 0;
BA_ "GenMsgCycleTime" BO_ 1146 200;
BA_ "GenMsgSendType" BO_ 1146 0;
BA_ "GenMsgCycleTime" BO_ 1130 10;
BA_ "GenMsgSendType" BO_ 1130 0;
BA_ "GenMsgCycleTime" BO_ 540 50;
BA_ "GenMsgSendType" BO_ 540 0;
BA_ "GenMsgCycleTime" BO_ 541 50;
BA_ "GenMsgSendType" BO_ 541 0;
BA_ "GenMsgCycleTime" BO_ 793 100;
BA_ "GenMsgSendType" BO_ 793 0;
BA_ "GenMsgCycleTime" BO_ 814 100;
BA_ "GenMsgSendType" BO_ 814 0;
BA_ "GenMsgCycleTime" BO_ 1303 1000;
BA_ "GenMsgSendType" BO_ 1303 0;
BA_ "GenMsgCycleTime" BO_ 845 100;
BA_ "GenMsgSendType" BO_ 845 0;
BA_ "GenMsgSendType" BO_ 1976 1;
BA_ "GenMsgSendType" BO_ 2015 4;
BA_ "GenMsgSendType" BO_ 1888 4;
BA_ "GenMsgSendType" BO_ 1896 4;
BA_ "GenMsgSendType" BO_ 1546 4;
BA_ "GenMsgSendType" BO_ 1547 4;
BA_ "GenMsgCycleTime" BO_ 201 10;
BA_ "GenMsgSendType" BO_ 201 0;
BA_ "GenMsgCycleTime" BO_ 404 25;
BA_ "GenMsgSendType" BO_ 404 0;
BA_ "GenMsgCycleTime" BO_ 479 25;
BA_ "GenMsgSendType" BO_ 479 0;
BA_ "GenMsgCycleTime" BO_ 707 50;
BA_ "GenMsgSendType" BO_ 707 0;
BA_ "GenMsgCycleTime" BO_ 945 100;
BA_ "GenMsgSendType" BO_ 945 0;
BA_ "GenMsgCycleTime" BO_ 977 100;
BA_ "GenMsgSendType" BO_ 977 0;
BA_ "GenMsgCycleTime" BO_ 1217 500;
BA_ "GenMsgSendType" BO_ 1217 0;
BA_ "GenMsgCycleTime" BO_ 1233 500;
BA_ "GenMsgSendType" BO_ 1233 0;
BA_ "GenMsgCycleTime" BO_ 251 10;
BA_ "GenMsgSendType" BO_ 251 0;
BA_ "GenMsgCycleTime" BO_ 560 20;
BA_ "GenMsgSendType" BO_ 560 0;
BA_ "GenMsgCycleTime" BO_ 328 1000;
BA_ "GenMsgSendType" BO_ 328 0;
BA_ "GenMsgCycleTime" BO_ 1071 100;
BA_ "GenMsgSendType" BO_ 1071 0;
BA_ "GenMsgCycleTime" BO_ 1127 50;
BA_ "GenMsgSendType" BO_ 1127 0;
BA_ "GenMsgSendType" BO_ 1059 1;
BA_ "GenMsgCycleTime" BO_ 1104 100;
BA_ "GenMsgSendType" BO_ 1104 0;
BA_ "GenMsgCycleTime" BO_ 875 100;
BA_ "GenMsgSendType" BO_ 875 0;
BA_ "GenMsgCycleTime" BO_ 886 100;
BA_ "GenMsgSendType" BO_ 886 0;
BA_ "GenMsgCycleTime" BO_ 1291 500;
BA_ "GenMsgSendType" BO_ 1291 0;
BA_ "GenMsgCycleTime" BO_ 871 100;
BA_ "GenMsgSendType" BO_ 871 0;
BA_ "GenMsgCycleTime" BO_ 893 100;
BA_ "GenMsgSendType" BO_ 893 0;
BA_ "GenMsgSendType" BO_ 1095 1;
BA_ "GenMsgCycleTime" BO_ 217 10;
BA_ "GenMsgSendType" BO_ 217 0;
BA_ "GenMsgCycleTime" BO_ 498 20;
BA_ "GenMsgSendType" BO_ 498 0;
BA_ "GenMsgCycleTime" BO_ 499 30;
BA_ "GenMsgSendType" BO_ 499 0;
BA_ "GenMsgCycleTime" BO_ 481 30;
BA_ "GenMsgSendType" BO_ 481 0;
BA_ "GenMsgCycleTime" BO_ 1523 100;
BA_ "GenMsgSendType" BO_ 1523 0;
BA_ "GenMsgCycleTime" BO_ 1142 200;
BA_ "GenMsgSendType" BO_ 1142 0;
BA_ "GenMsgCycleTime" BO_ 1046 200;
BA_ "GenMsgSendType" BO_ 1046 0;
BA_ "GenMsgCycleTime" BO_ 858 10;
BA_ "GenMsgSendType" BO_ 858 0;
BA_ "GenMsgCycleTime" BO_ 1134 200;
BA_ "GenMsgSendType" BO_ 1134 0;
BA_ "GenMsgCycleTime" BO_ 1345 200;
BA_ "GenMsgSendType" BO_ 1345 0;
BA_ "GenMsgCycleTime" BO_ 1123 10;
BA_ "GenMsgSendType" BO_ 1123 0;
BA_ "GenMsgCycleTime" BO_ 874 100;
BA_ "GenMsgSendType" BO_ 874 0;
BA_ "GenMsgCycleTime" BO_ 1047 200;
BA_ "GenMsgSendType" BO_ 1047 0;
BA_ "GenMsgCycleTime" BO_ 1144 200;
BA_ "GenMsgSendType" BO_ 1144 0;
BA_ "GenMsgSendType" BO_ 1531 1;
BA_ "GenMsgSendType" BO_ 1087 4;
BA_ "GenMsgCycleTime" BO_ 573 50;
BA_ "GenMsgSendType" BO_ 573 0;
BA_ "GenMsgCycleTime" BO_ 485 10;
BA_ "GenMsgSendType" BO_ 485 0;
BA_ "GenMsgCycleTime" BO_ 455 10;
BA_ "GenMsgSendType" BO_ 455 0;
BA_ "GenMsgCycleTime" BO_ 562 10;
BA_ "GenMsgSendType" BO_ 562 0;
BA_ "GenMsgCycleTime" BO_ 532 50;
BA_ "GenMsgSendType" BO_ 532 0;
BA_ "GenMsgCycleTime" BO_ 840 50;
BA_ "GenMsgSendType" BO_ 840 0;
BA_ "GenMsgCycleTime" BO_ 842 50;
BA_ "GenMsgSendType" BO_ 842 0;
BA_ "GenMsgCycleTime" BO_ 381 100;
BA_ "GenMsgSendType" BO_ 381 0;
BA_ "GenMsgCycleTime" BO_ 837 100;
BA_ "GenMsgSendType" BO_ 837 0;
BA_ "GenMsgCycleTime" BO_ 851 100;
BA_ "GenMsgSendType" BO_ 851 0;
BA_ "GenMsgCycleTime" BO_ 355 20;
BA_ "GenMsgSendType" BO_ 355 0;
BA_ "GenMsgCycleTime" BO_ 1225 500;
BA_ "GenMsgSendType" BO_ 1225 0;
BA_ "GenMsgCycleTime" BO_ 1072 100;
BA_ "GenMsgSendType" BO_ 1072 0;
BA_ "GenMsgCycleTime" BO_ 1149 400;
BA_ "GenMsgSendType" BO_ 1149 0;
BA_ "GenMsgCycleTime" BO_ 1150 400;
BA_ "GenMsgSendType" BO_ 1150 0;
BA_ "GenMsgSendType" BO_ 1060 1;
BA_ "GenSigStartValue" SG_ 497 SysPwrMdV_h1_HS 1;
BA_ "GenSigStartValue" SG_ 1055 signal_config_id 28673;
BA_ "GenSigStartValue" SG_ 1139 VINBCM_H1_HS 255;
BA_ "GenSigStartValue" SG_ 1130 VehLckngSta_H1_HS 7;
BA_ "GenSigStartValue" SG_ 793 BatVol_HS 16383;
BA_ "GenSigStartValue" SG_ 1303 BatSOC_HS 187;
BA_ "GenSigStartValue" SG_ 479 EnASSSta_HS 1;
BA_ "GenSigStartValue" SG_ 871 MusSrcMd_HS 15;
BA_ "GenSigStartValue" SG_ 871 RdoFrqcVal_HS 65535;
BA_ "GenSigStartValue" SG_ 893 NavDircn_HS 63;
BA_ "GenSigStartValue" SG_ 893 NavDist_HS 32767;
BA_ "GenSigStartValue" SG_ 874 ClstrOvrSpdThrshld_HS 24;
BA_ "GenSigLongName" SG_ 1047 ClstrDspdIgnRelayWrnng_HS "Cluster Displayed Ignition Relay Warning";
BA_ "GenSigLongName" SG_ 1047 ClstrDspdPEWrnng_HS "Cluster Displayed Passive Entry Warning";
BA_ "GenSigLongName" SG_ 1047 ClstrDspdRBrkLghtWrnng_HS "Cluster Displayed Right Brake Light Warning";
BA_ "GenSigLongName" SG_ 1047 ClstrDspdRDipdBeamLW_HS "Cluster Displayed Right Dipped Beam Light Warning";
BA_ "GenSigLongName" SG_ 1047 ClstrDspdRDircnIndLW_HS "Cluster Displayed Right Direction Indication Light Warning";
BA_ "GenSigLongName" SG_ 1047 ClstrDspdRevsLampWrnng_HS "Cluster Displayed Reverse Lamp Warning";
BA_ "GenSigLongName" SG_ 1047 ClstrDspdRrFogLghtW_HS "Cluster Displayed Rear Fog Light Warning";
BA_ "GenSigLongName" SG_ 1047 ClstrDspdRSideLghtW_HS "Cluster Displayed Right Side Light Warning";
BA_ "GenSigLongName" SG_ 1047 ClstrDspdSpStBtnWrnng_HS "Cluster Displayed Stop Start Button Warning";
BA_ "GenSigStartValue" SG_ 1087 sm_signal_config_id_h1 28673;
BA_ "GenSigStartValue" SG_ 840 WhlGndVelLDrvnV_HS 1;
BA_ "GenSigStartValue" SG_ 840 WhlGndVelRDrvnV_HS 1;
BA_ "GenSigStartValue" SG_ 842 WhlGndVelLNonDrvnV_HS 1;
BA_ "GenSigStartValue" SG_ 842 WhlGndVelRNonDrvnV_HS 1;
BA_ "GenSigLongName" SG_ 837 AutoHoldMsg_HS "Autohold Message";
BA_ "GenSigStartValue" SG_ 1149 FLTirePrs_HS 55;
BA_ "GenSigStartValue" SG_ 1149 FLTireTem_HS 45;
BA_ "GenSigStartValue" SG_ 1149 FRTirePrs_HS 55;
BA_ "GenSigStartValue" SG_ 1149 FRTireTem_HS 45;
BA_ "GenSigStartValue" SG_ 1149 RLTirePrs_HS 55;
BA_ "GenSigStartValue" SG_ 1149 RLTireTem_HS 45;
BA_ "GenSigStartValue" SG_ 1149 RRTirePrs_HS 55;
BA_ "GenSigStartValue" SG_ 1149 RRTireTem_HS 45;
BA_ "GenSigStartValue" SG_ 1150 TPMSAutoLoctnCm_HS 1;
BA_ "GenSigStartValue" SG_ 1150 TPMSIdficnLrnCm_HS 1;
VAL_ 1522 keep_network_AC_HS 1 "keep network request" 0 "no keep network request" ;
VAL_ 1205 wake_network_AC_HS 1 "wake-up network request" 0 "no wake-up network request" ;
VAL_ 497 PwrMdMstrAccryA_H1_HS 1 "Active" 0 "Inactive" ;
VAL_ 497 PwrMdMstrRunCrkA_H1_HS 1 "Active" 0 "Inactive" ;
VAL_ 497 SysOpnlMd_HS 5 "Diagnosic or Reprogramming(Reserve)" 4 "Storage Mode" 3 "Show Room" 2 "Transit Mode" 1 "Manufacturing Mode" 0 "Normal Mode" ;
VAL_ 497 SysPwrMdV_h1_HS 1 "Invalid" 0 "Valid" ;
VAL_ 497 SysPwrMd_h1_HS 3 "Crank" 2 "Run" 1 "ACC" 0 "Off" ;
VAL_ 497 SysVolMd_HS 3 "Illegal System  Voltage" 2 "High System Voltage" 1 "Low System Voltage" 0 "Normal" ;
VAL_ 497 SysVolMdV_HS 1 "Invalid" 0 "Valid" ;
VAL_ 497 SysVolV_HS 1 "Invalid" 0 "Valid" ;
VAL_ 1344 VehOdoV_H1_HS 1 "Invalid" 0 "Valid" ;
VAL_ 795 PwrMdMstrAccryWkupA_HS 1 "TRUE" 0 "FALSE" ;
VAL_ 795 PwrMdMstrIgnA_HS 1 "TRUE" 0 "FALSE" ;
VAL_ 1055 network_mode 2 "normal" 1 "shutdown" 0 "start-up" ;
VAL_ 1055 signal_config_id 8272 "config: NMC/OTS2/base" ;
VAL_ 1146 AmbtLghtLvl_H1_HS 3 "Level 3  ( Reserved )" 2 "Level 2 ( Dipped Beam On ) Request" 1 "Level 1 ( Reserved for position lamp On Request )" 0 " Level 0 ( Day: position lamp and dipped beam off )" ;
VAL_ 1146 LghtSwPosSts_H1_HS 7 "reserved" 6 "reserved" 5 "reserved" 4 "Unknow position" 3 "Dipped Beam" 2 "Side Lamp" 1 "Switch is on 'Auto' position           " 0 "Switch is on 'Off' position" ;
VAL_ 1130 BCMEmgcSp_HS 1 "TRUE" 0 "FALSE" ;
VAL_ 1130 BCMPwrMdHwdSta_HS 3 "CRANK" 2 "RUN" 1 "ACC " 0 "OFF" ;
VAL_ 1130 BCMPwrMdHwdStaV_HS 1 "Invalid" 0 "Valid" ;
VAL_ 1130 BCMSSBA_HS 1 "Active " 0 "Inactive" ;
VAL_ 1130 BCMSSBAV_HS 1 "Invalid" 0 "Valid" ;
VAL_ 1130 BntOpenSts_H1_HS 3 "Reserved" 2 "Bonnet Switch Disconnect" 1 "Bonnet Open" 0 "Bonnet Closed" ;
VAL_ 1130 DipdBeamLghtOn_HS 1 "TRUE" 0 "FALSE" ;
VAL_ 1130 DrvrDoorOpenSts_H1_HS 3 "Driver Door Full Open" 2 "Driver Door Ajar" 1 "Driver Door Open(For latch switch can't detect door ajar status)" 0 "Driver Door Closed" ;
VAL_ 1130 FrtFogLghtOn_H1_HS 1 "TRUE" 0 "FALSE" ;
VAL_ 1130 FrtPsngDoorOpenSts_H1_HS 3 "Front Passenger Door Full Open" 2 "Front Passenger Door Ajar" 1 "Front Passenger Open(latch switch cann¡®t detect door ajar statu" 0 "Front Passenger Door Closed" ;
VAL_ 1130 LDircnIO_HS 1 "TRUE" 0 "FALSE" ;
VAL_ 1130 LdspcOpenSts_H1_HS 3 "Reserved" 2 "Reserved" 1 "Load Space Open" 0 "Load Space Closed" ;
VAL_ 1130 MainBeamLghtOn_H1_HS 1 "TRUE" 0 "FALSE" ;
VAL_ 1130 RDircnIO_HS 1 "TRUE" 0 "FALSE" ;
VAL_ 1130 RRDoorOpenSts_HS 3 "Rear right  Door Full open" 2 "Rear right  Door Ajar" 1 "Rear right  Door Open(For latch switch cannot detect doorajar status)" 0 "Rear right Door Closed" ;
VAL_ 1130 RrFogLghtF_H1_HS 1 "TRUE" 0 "FALSE" ;
VAL_ 1130 RrFogLghtOn_H1_HS 1 "TRUE" 0 "FALSE" ;
VAL_ 1130 VehLckngSta_H1_HS 7 "Unknow" 6 "Reserved" 5 "Reserved" 4 "Super locked" 3 "Exterior Locked" 2 "Interior Locked" 1 "Signal Position Entry Unlocked" 0 "Unlocked" ;
VAL_ 1130 VehSideLghtSts_H1_HS 3 "All side light and license plate light on" 2 "Right side light on only" 1 "Left side light on only" 0 "No side light on " ;
VAL_ 540 BCMGearShftParkNtrlESR_HS 1 "TRUE" 0 "FALSE" ;
VAL_ 540 BCMNoSmtKeyInVehRmndr_HS 1 "TRUE" 0 "FALSE" ;
VAL_ 540 BCMNoSmtKeyPressBrkTRR_HS 1 "TRUE" 0 "FALSE" ;
VAL_ 540 BCMNoSmtKeyPressClToRR_HS 1 "TRUE" 0 "FALSE" ;
VAL_ 540 BCMPressBrkRmndr_HS 1 "TRUE" 0 "FALSE" ;
VAL_ 540 BCMPressClRmndr_HS 1 "TRUE" 0 "FALSE" ;
VAL_ 540 BCMPutSmtKeyToBkupPosR_HS 1 "TRUE" 0 "FALSE" ;
VAL_ 540 BCMRunCrkF_HS 1 "TRUE" 0 "FALSE" ;
VAL_ 540 BCMShftParkRmndr_HS 1 "TRUE" 0 "FALSE" ;
VAL_ 540 BCMSSBFltSts_HS 7 "Reserved" 6 "Reserved" 5 "switch failed" 4 "Open Circuit" 3 "Stuck" 2 "short to Battery" 1 "short to GND" 0 "No Fault" ;
VAL_ 540 BCMTakeSmtKeyOutOfSR_HS 1 "TRUE" 0 "FALSE" ;
VAL_ 540 DayTimeRunningLghtF_HS 1 "TRUE" 0 "FALSE" ;
VAL_ 540 DrvrWndOpenRmndr_HS 1 "TRUE" 0 "FALSE" ;
VAL_ 540 FrtSideLghtF_HS 1 "TRUE" 0 "FALSE" ;
VAL_ 540 LBrkLghtF_HS 1 "TRUE" 0 "FALSE" ;
VAL_ 540 LDipdBeamLghtF_HS 1 "TRUE" 0 "FALSE" ;
VAL_ 540 LDircnIndLghtF_H1_HS 1 "TRUE" 0 "FALSE" ;
VAL_ 540 PEPSAntFlt_HS 1 "TRUE" 0 "FALSE" ;
VAL_ 540 RBrkLghtF_HS 1 "TRUE" 0 "FALSE" ;
VAL_ 540 RDipdBeamLghtF_HS 1 "TRUE" 0 "FALSE" ;
VAL_ 540 RDircnIndLghtF_H1_HS 1 "TRUE" 0 "FALSE" ;
VAL_ 540 RevsLghtF_H1_HS 1 "TRUE" 0 "FALSE" ;
VAL_ 540 RrSideLghtF_HS 1 "TRUE" 0 "FALSE" ;
VAL_ 540 ScurtAlrmSts_HS 7 "not used" 6 "full alarm with volumetrics" 5 "part alarm with volumetrics" 4 "not used" 3 "not used" 2 "full alarm without volumetrics" 1 "part alarm without volumetrics" 0 "off" ;
VAL_ 540 ScurtKeyBatLow_HS 1 "TRUE" 0 "FALSE" ;
VAL_ 540 ScurtKeyInvd_HS 1 "TRUE" 0 "FALSE" ;
VAL_ 540 ShifterLckRlseBrkReqA_HS 1 "TRUE" 0 "FALSE" ;
VAL_ 540 SrfOpenRmndr_HS 1 "TRUE" 0 "FALSE" ;
VAL_ 540 SSBEnOffRmndr_HS 3 "Double Press Button Again To Turn Engine Off Reminder" 2 "Long Press Button To Turn Engine Off Reminder" 1 "Press Button Again To Turn Engine Off Reminder" 0 "no warning request " ;
VAL_ 540 TakeKeyOutRmndr_HS 1 "TRUE" 0 "FALSE" ;
VAL_ 541 BCMSyncSmtKeyRmndr_HS 1 "TRUE" 0 "FALSE" ;
VAL_ 541 DrvrPWLInitnRmndr_HS 1 "TRUE" 0 "FALSE" ;
VAL_ 541 SrfInitnRmndr_HS 1 "TRUE" 0 "FALSE" ;
VAL_ 814 BatAgngSta_HS 7 "reserved" 6 "reserved" 5 "reserved" 4 "reserved" 3 "Replace reminding" 2 "Middle Aging" 1 "Little  Aging " 0 "Good" ;
VAL_ 814 GenrSta_HS 7 "Reserved" 6 "Reserved" 5 "Reserved" 4 "Reserved" 3 "generator running in default state" 2 "generator failed" 1 "generator lost communication" 0 "generator is ok" ;
VAL_ 1303 BatSOC_HS 254 "reserved" 253 "reserved" 252 "reserved" 251 "reserved" ;
VAL_ 1303 VehLdShedLvl_H1_HS 7 "reserved" 6 "reserved" 5 "reserved" 4 "Power management direct current converter(PMDC)-broken" 3 "High Power Risk" 2 "Middle Power Risk" 1 "Low Power Risk" 0 "No Power Risk" ;
VAL_ 845 EmgcCallFlrSts_HS 3 "Invalid" 2 "ECall Function Heavy Level failure indication(Red)" 1 "ECall Function Light Level failure indication(Orange)" 0 "ECall Function No failure(Indication off)" ;
VAL_ 201 CCA_HS 1 "TRUE" 0 "FALSE" ;
VAL_ 201 CCEnbd_HS 1 "TRUE" 0 "FALSE" ;
VAL_ 201 En12VoltStrMotCmddOn_HS 1 "TRUE" 0 "FALSE" ;
VAL_ 201 EnRunA_HS 1 "TRUE" 0 "FALSE" ;
VAL_ 201 EnSpdSts_HS 3 "Invalid" 2 "Reserved" 1 "Degraded Operation" 0 "Normal Operation" ;
VAL_ 404 DrvrShftCtrlTrgtGear_HS 8 "Eighth Gear" 7 "Seventh Gear" 6 "Sixth Gear" 5 "Fifth Gear" 4 "Fourth Gear" 3 "Third Gear" 2 "Second Gear" 1 "First Gear" 0 "Not Supported" ;
VAL_ 404 TrShftLvrPos_HS 15 "Lever Position Unknown" 11 "Forward Range H" 10 "Forward Range G" 9 "Forward Range F" 8 "Forward Range E" 7 "Forward Range D" 6 "Forward Range C" 5 "Forward Range B" 4 "Forward Range A" 3 "Neutral Range" 2 "Reverse Range" 1 "Park Range" 0 "Between Ranges" ;
VAL_ 404 TrShftLvrPosV_HS 1 "Invalid" 0 "Valid" ;
VAL_ 404 TrShftPtrnASts_HS 6 "PT Protection Pattern Active" 5 "PT Non-Protection Pattern Active" 4 "Shift Pattern 4 Active" 3 "Shift Pattern 3 Active" 2 "Shift Pattern 2 Active" 1 "Shift Pattern 1 Active" 0 "Default Shift Pattern Active" ;
VAL_ 404 TrTapUpTapDwnMdSts_HS 2 "Electronic Range Select Active" 1 "Driver Shift Control Active" 0 "No Activation" ;
VAL_ 479 EnASSSta_HS 3 "Engine Stopping" 2 "Engine Starting" 1 "Engine Running" 0 "Engine Off" ;
VAL_ 707 EcoDrvngAIO_HS 1 "TRUE" 0 "FALSE" ;
VAL_ 707 EcoDrvngDspStsGearSIS_HS 3 "Reserved" 2 "Gear Shift Down" 1 "Gear Shift Up" 0 "No Shift" ;
VAL_ 707 EcoDrvngDspStsRcmndFG_HS 15 "Unused and Reserved 7" 14 "Unused and Reserved 6" 13 "Unused and Reserved 5" 12 "Unused and Reserved 4" 11 "Unused and Reserved 3" 10 "Unused and Reserved 2" 9 "Unused and Reserved 1" 8 "Eighth Gear" 7 "Seventh Gear" 6 "Sixth Gear" 5 "Fifth Gear" 4 "Fouth Gear" 3 "Third Gear" 2 "Second Gear" 1 "First Gear" 0 "None" ;
VAL_ 707 ECODrvngSpdRutA_HS 1 "TRUE" 0 "FALSE" ;
VAL_ 945 ASSInhBtnLampOn_HS 1 "TRUE" 0 "FALSE" ;
VAL_ 945 ASSInhIO_HS 1 "TRUE" 0 "FALSE" ;
VAL_ 945 ASSStsLampOn_HS 1 "TRUE" 0 "FALSE" ;
VAL_ 945 ASSWrnngLampOn_HS 1 "TRUE" 0 "FALSE" ;
VAL_ 945 CCFltPrst_HS 1 "TRUE" 0 "FALSE" ;
VAL_ 945 ECMClsDoorToAutoStR_HS 1 "TRUE" 0 "FALSE" ;
VAL_ 945 ECMFasnSbltToAutoStR_HS 1 "TRUE" 0 "FALSE" ;
VAL_ 945 ECMPressClBrkRmndr_HS 3 "Reserved" 2 "Press the brake" 1 "Press the clutch" 0 "No message" ;
VAL_ 945 ECMShftNtrlToAutoStR_HS 1 "TRUE" 0 "FALSE" ;
VAL_ 977 EnEmsnRltdMalfA_HS 1 "TRUE" 0 "FALSE" ;
VAL_ 977 EnEmsnRltdMalfIndReq_HS 7 "Reserved" 6 "Reserved" 5 "Reserved" 4 "Flashing 1/2 Hertz Indication" 3 "Flashing 2 Hertz Indication" 2 "Flashing 1 Hertz Indication" 1 "No Indication" 0 "Continuous Indication" ;
VAL_ 977 EnGPFLampOnSts_HS 3 "GPF Full Reminder" 2 "GPF Regeneration Active" 1 "GPF Regeneration Reminder" 0 "off" ;
VAL_ 977 EnNonEmsnRltdMalfA_HS 1 "TRUE" 0 "FALSE" ;
VAL_ 1217 EnClntTemV_HS 1 "Invalid" 0 "Valid" ;
VAL_ 1233 EnOilPrsLowIO_HS 1 "TRUE" 0 "FALSE" ;
VAL_ 251 SpdAstSysStsECM_HS 7 "Reserved" 6 "Active (Passive)" 5 "Fault" 4 "Overspeed" 3 "Entry Conditions Incorrect" 2 "Standby" 1 "Active (Limiting)" 0 "Off" ;
VAL_ 560 EPBSysAudWrnngReq_HS 2 "Warning #2" 1 "Warning #1" 0 "Off" ;
VAL_ 560 EPBSysDspMsgReq_HS 7 "Message #7" 6 "Message #6" 5 "Message #5" 4 "Message #4" 3 "Message #3" 2 "Message #2" 1 "Message #1" 0 "Off" ;
VAL_ 560 EPBSysStsIndReq_HS 3 "Flash Rate #2 Indication" 2 "Flash Rate #1 Indication" 1 "Continuous Indication" 0 "No Indication" ;
VAL_ 560 EPBSysWrnngIndReq_HS 3 "Flash Rate #2 Indication" 2 "Flash Rate #1 Indication" 1 "Continuous Indication" 0 "No Indication" ;
VAL_ 328 EPSFlrSts_HS 3 "Invalid" 2 "EPS Heavy Level failure indication£¨Red£©" 1 "EPS Light Level failure indication£¨Orange£©" 0 "EPS No failure(Indication off)" ;
VAL_ 1071 keep_network_ESCL_HS 1 "keep network request" 0 "no keep network request" ;
VAL_ 1127 ESCLFlrIndCmd_HS 3 "Functional limitation failure detected" 2 "Steering wheel is blocked" 1 "Defect failure detected" 0 "No defect failure detected" ;
VAL_ 1059 wake_network_ESCL_HS 1 "wake-up network request" 0 "no wake-up network request" ;
VAL_ 1104 keep_network_FICM_HS 1 "keep network request" 0 "no keep network request" ;
VAL_ 875 ChmA_HS 1 "TRUE" 0 "FALSE" ;
VAL_ 875 FICMTemUntAdj_HS 2 "Not Available" 1 "Fahrenheit Degree(¨H)" 0 "Celsius Degree(¡æ)" ;
VAL_ 875 LanggSetngAdj_HS 24 "Thai" 23 "Russian" 22 "Slovak" 21 "Czech" 20 "Hungarian" 19 "Italian" 18 "Traditional Chinese" 17 "Korean" 16 "Turkish" 15 "Polish" 14 "German" 13 "Arabic" 12 "Japanese" 11 "Greek" 10 "Danish" 9 "Finnish" 8 "Norwegian" 7 "Portuguese" 6 "Dutch" 5 "Spanish" 4 "French" 3 "Swedish" 2 "NA English" 1 "UK English" 0 "Simplified Chinese" ;
VAL_ 875 LanggSetngAdjReqA_HS 1 "TRUE" 0 "FALSE" ;
VAL_ 886 FICMDistUnitAdjtReqA_HS 1 "TRUE" 0 "FALSE" ;
VAL_ 1291 CalendarAdjReqA_HS 1 "TRUE" 0 "FALSE" ;
VAL_ 1291 CalendarMonthAdj_HS 15 "Reserved" 14 "Reserved" 13 "Reserved" 12 "December" 11 "November" 10 "October" 9 "September" 8 "August" 7 "July" 6 "June" 5 "May" 4 "April" 3 "March" 2 "February" 1 "January" 0 "Unknown" ;
VAL_ 1291 TimeAdjReqA_HS 1 "TRUE" 0 "FALSE" ;
VAL_ 1291 TimeDspFmtAdj_HS 1 "24 hour mode" 0 "12 hour mode" ;
VAL_ 871 FICMDistUntAdj_HS 1 "miles" 0 "km" ;
VAL_ 871 FICMFuelCsumpUntAdj_HS 2 "mpg(US)" 1 "mpg(UK)" 0 "L/100km" ;
VAL_ 871 FICMFuelCsumpUntAdjARA_HS 1 "TRUE" 0 "FALSE" ;
VAL_ 871 FICMOverSpdFnCrntSts_HS 1 "On" 0 "Off" ;
VAL_ 871 FICMOvrSpdThrshldAdjtRA_HS 1 "TRUE" 0 "FALSE" ;
VAL_ 871 FICMTemUntAdjtReqA_HS 1 "TRUE" 0 "FALSE" ;
VAL_ 871 FICMTyrePressureUntAdj_HS 2 "Psi" 1 "kpa" 0 "bar" ;
VAL_ 871 FICMTyrePressureUntAdjtReqA_HS 1 "TRUE" 0 "FALSE" ;
VAL_ 871 FICMVehMntnceSts_HS 3 "Reserved" 2 "Maintain immediately" 1 "Suggest to Maintain" 0 "Status OK" ;
VAL_ 871 MusSrcMd_HS 15 "invalid" 9 "Team Audio" 8 "Karaoke" 7 "Cache Audio" 6 "USB Audio" 5 "Online Audio" 4 "BT Audio" 3 "Audio Book" 2 "Network Station" 1 "Local Station" 0 "OFF" ;
VAL_ 871 RdoFrqcVal_HS 65535 "invalid" ;
VAL_ 893 NavDircn_HS 63 "invalid" 15 "into tube" 14 "Arrive the Destination" 13 "Arrive Toll Station" 12 "Arrive Srvice Zone" 11 "Out Cirle Zone" 10 "into Circle Zone" 9 "Arrive Middle Pointer" 8 "Driver Straight" 7 "Back" 6 "Right After" 5 "Left After" 4 "right Head" 3 "Left Head" 2 "turn Right" 1 "turn Left" 0 "SelfCar Logo" ;
VAL_ 893 NavDist_HS 32767 "invalid" ;
VAL_ 893 NavDistUnit_HS 1 "0.1km" 0 "m" ;
VAL_ 1095 wake_network_FICM_HS 1 "wake-up network request" 0 "no wake-up network request" ;
VAL_ 217 ASSInhBtnA_HS 1 "TRUE" 0 "FALSE" ;
VAL_ 498 SysBPM_HS 3 "Crank" 2 "Run" 1 "ACC" 0 "Off" ;
VAL_ 498 SysBPMEnbd_HS 1 "TRUE" 0 "FALSE" ;
VAL_ 499 PfTrTapUpDwnEnbSwSta_HS 3 "Illegal Enable Switch State Active" 2 "Electronic Range Select Enable Switch Active" 1 "Driver Shift Control Enable Switch Active" 0 "No Activation" ;
VAL_ 499 PfTrTapUpDwnSecySwSta_HS 3 "Illegal Up/Down Switch State Active" 2 "Decrement Switch Active" 1 "Increment Switch Active" 0 "No Activation" ;
VAL_ 499 PfTrTapUpDwnSwSta_HS 3 "Illegal Up/Down Switch State Active" 2 "Decrement Switch Active" 1 "Increment Switch Active" 0 "No Activation" ;
VAL_ 499 TrPfShftPtrnSw1A_HS 1 "TRUE" 0 "FALSE" ;
VAL_ 499 TrPfShftPtrnSw4A_HS 1 "TRUE" 0 "FALSE" ;
VAL_ 481 CCSwStsCanclSwA_HS 1 "True" 0 "False" ;
VAL_ 481 CCSwStsDisDecSwA_HS 1 "TRUE" 0 "FALSE" ;
VAL_ 481 CCSwStsDistIncSwA_HS 1 "TRUE" 0 "FALSE" ;
VAL_ 481 CCSwStsOnSwA_HS 1 "True" 0 "False" ;
VAL_ 481 CCSwStsRsmSwA_HS 1 "True" 0 "False" ;
VAL_ 481 CCSwStsSetSwA_HS 1 "True" 0 "False" ;
VAL_ 481 CCSwStsSpdDecSwA_HS 1 "True" 0 "False" ;
VAL_ 481 CCSwStsSpdIncSwA_HS 1 "True" 0 "False" ;
VAL_ 481 CCSwStsSwDataIntgty_HS 3 "Illegal Range" 2 "Failure Detected" 1 "Data Invalid" 0 "Data Valid" ;
VAL_ 1523 keep_network_IPK_HS 1 "keep network request" 0 "no keep network request" ;
VAL_ 1046 AirbagWrnngIndF_HS 1 "TRUE" 0 "FALSE" ;
VAL_ 1046 Clstr10KmTick_HS 1 "TRUE" 0 "FALSE" ;
VAL_ 1046 DspMeasSys_HS 1 "MPH" 0 "kph" ;
VAL_ 1046 FuelLvlPcntV_HS 1 "Invalid" 0 "Valid" ;
VAL_ 858 AvgFuelCsumpV_HS 1 "Invalid" 0 "Valid" ;
VAL_ 858 ChmCmdSndLoctnFL_HS 1 "TRUE" 0 "FALSE" ;
VAL_ 858 ChmCmdSndLoctnFR_HS 1 "TRUE" 0 "FALSE" ;
VAL_ 858 ChmCmdSndLoctnRL_HS 1 "TRUE" 0 "FALSE" ;
VAL_ 858 ChmCmdSndLoctnRR_HS 1 "TRUE" 0 "FALSE" ;
VAL_ 858 ChmCmdSndTone_HS 15 "Reserved" 14 "Reserved" 13 "Reserved" 12 "Reserved" 11 "Reserved" 10 "Reserved" 9 "Reserved" 8 "Reserved" 7 "Reserved" 6 "Reserved" 5 "Gong (2000 Hz)" 4 "Gong (750 Hz)" 3 "Beep (2000 Hz)" 2 "Beep (750 Hz)" 1 "Click" 0 "Clack" ;
VAL_ 858 ClstrDspdVehSpd_HS 255 "Speed Signal Missing Error of SCS" ;
VAL_ 858 IPCAccryA_HS 1 "TRUE" 0 "FALSE" ;
VAL_ 858 IPCRunCrkA_HS 1 "TRUE" 0 "FALSE" ;
VAL_ 858 IPCRunCrkF_HS 1 "TRUE" 0 "FALSE" ;
VAL_ 858 IPCSSBA_HS 1 "TRUE" 0 "FALSE" ;
VAL_ 858 IPCSSBAV_HS 1 "Invalid" 0 "Valid" ;
VAL_ 858 IPCSSBFltSts_HS 7 "Reserved" 6 "Reserved" 5 "switch failed" 4 "Open Circuit" 3 "Stuck" 2 "short to Battery" 1 "short to GND" 0 "No Fault" ;
VAL_ 858 LanggSetng_HS 24 "Thai" 23 "Russian" 22 "Slovak" 21 "Czech" 20 "Hungarian" 19 "Italian" 18 "Traditional Chinese" 17 "Korean" 16 "Turkish" 15 "Polish" 14 "German" 13 "Arabic" 12 "Japanese" 11 "Greek" 10 "Danish" 9 "Finnish" 8 "Norwegian" 7 "Portuguese" 6 "Dutch" 5 "Spanish" 4 "French" 3 "Swedish" 2 "NA English" 1 "UK English" 0 "Simplified Chinese" ;
VAL_ 1345 CalendarMonth_HS 15 "Reserved" 14 "Reserved" 13 "Reserved" 12 "December" 11 "November" 10 "October" 9 "September" 8 "August" 7 "July" 6 "June" 5 "May" 4 "April" 3 "March" 2 "February" 1 "January" 0 "Unknown" ;
VAL_ 1345 TimeDspFmt_HS 1 "24 hour mode" 0 "12 hour mode" ;
VAL_ 1123 IPCEcoDrvngSwA_HS 1 "TRUE" 0 "FALSE" ;
VAL_ 874 ClstrDistUnt_HS 1 "miles" 0 "km" ;
VAL_ 874 ClstrFuelCsumpUnt_HS 3 "km/L" 2 "mpg(US)" 1 "mpg(UK)" 0 "L/100km" ;
VAL_ 874 ClstrOverSpdFnHstrSts_HS 1 "On" 0 "Off" ;
VAL_ 874 ClstrTemUnt_HS 3 "Reserved" 2 "Not Available" 1 "Fahrenheit Degree(¨H)" 0 "Celsius Degree(¡æ)" ;
VAL_ 874 ClstrTyrePressureUnt_HS 2 "Psi" 1 "kpa" 0 "bar" ;
VAL_ 1047 ClstrDspdABSWrnng_HS 1 "Warning" 0 "No Warning" ;
VAL_ 1047 ClstrDspdAirbagWrnng_HS 1 "Warning" 0 "No Warning" ;
VAL_ 1047 ClstrDspdAltrWrnng_HS 1 "Warning" 0 "No Warning" ;
VAL_ 1047 ClstrDspdASpdLmtrWrnng_HS 1 "Warning" 0 "No Warning" ;
VAL_ 1047 ClstrDspdAutoholdWrnng_HS 1 "Warning" 0 "No Warning" ;
VAL_ 1047 ClstrDspdBatRplmntRqdW_HS 1 "Warning" 0 "No Warning" ;
VAL_ 1047 ClstrDspdBrkSysWrnng_HS 1 "Warning" 0 "No Warning" ;
VAL_ 1047 ClstrDspdCCWrnng_HS 1 "Warning" 0 "No Warning" ;
VAL_ 1047 ClstrDspdClntTemWrnng_HS 1 "Warning" 0 "No Warning" ;
VAL_ 1047 ClstrDspdClSwWrnng_HS 1 "Warning" 0 "No Warning" ;
VAL_ 1047 ClstrDspdDayTimeRLW_HS 1 "Warning" 0 "No Warning" ;
VAL_ 1047 ClstrDspdEleccParkngBW_HS 1 "Warning" 0 "No Warning" ;
VAL_ 1047 ClstrDspdEnDrvByWireW_HS 1 "Warning" 0 "No Warning" ;
VAL_ 1047 ClstrDspdEPSWrnng_HS 3 "Reserved" 2 "Serious Warning" 1 "General Warning" 0 "No Warning" ;
VAL_ 1047 ClstrDspdFuelLvlSgmt_HS 8 "8th Segment On" 7 "7th Segment On" 6 "6th Segment On" 5 "5th Segment On" 4 "4th Segment On" 3 "3th Segment On" 2 "2nd Segment On" 1 "1st Segment On" 0 "1st Segment Flash" ;
VAL_ 1047 ClstrDspdFuelSnsrWrnng_HS 1 "Warning" 0 "No Warning" ;
VAL_ 1047 ClstrDspdFuelSts_HS 3 "Reserved" 2 "Fuel Status Critical" 1 "Fuel Status Low" 0 "Fuel Status OK" ;
VAL_ 1047 ClstrDspdHDCWrnng_HS 1 "Warning" 0 "No Warning" ;
VAL_ 1047 ClstrDspdIgnRelayWrnng_HS 1 "Warning" 0 "No Warning" ;
VAL_ 1047 ClstrDspdInfoMsk_HS 1 "Use Data" 0 "Don¡®t Use Data" ;
VAL_ 1047 ClstrDspdInvdKeyWrnng_HS 1 "Warning" 0 "No Warning" ;
VAL_ 1047 ClstrDspdLBrkLghtWrnng_HS 1 "Warning" 0 "No Warning" ;
VAL_ 1047 ClstrDspdLDipdBeamLW_HS 1 "Warning" 0 "No Warning" ;
VAL_ 1047 ClstrDspdLDircnIndLW_HS 1 "Warning" 0 "No Warning" ;
VAL_ 1047 ClstrDspdLSideLghtW_HS 1 "Warning" 0 "No Warning" ;
VAL_ 1047 ClstrDspdMalfIndrLghtW_HS 1 "Warning" 0 "No Warning" ;
VAL_ 1047 ClstrDspdOilPrsLowW_HS 1 "Warning" 0 "No Warning" ;
VAL_ 1047 ClstrDspdPDCWrnng_HS 1 "Warning" 0 "No Warning" ;
VAL_ 1047 ClstrDspdPEWrnng_HS 1 "Warning" 0 "No Warning" ;
VAL_ 1047 ClstrDspdRBrkLghtWrnng_HS 1 "Warning" 0 "No Warning" ;
VAL_ 1047 ClstrDspdRDipdBeamLW_HS 1 "Warning" 0 "No Warning" ;
VAL_ 1047 ClstrDspdRDircnIndLW_HS 1 "Warning" 0 "No Warning" ;
VAL_ 1047 ClstrDspdRevsLampWrnng_HS 1 "Warning" 0 "No Warning" ;
VAL_ 1047 ClstrDspdRrFogLghtW_HS 1 "Warning" 0 "No Warning" ;
VAL_ 1047 ClstrDspdRSideLghtW_HS 1 "Warning" 0 "No Warning" ;
VAL_ 1047 ClstrDspdSASUncalWrnng_HS 1 "Warning" 0 "No Warning" ;
VAL_ 1047 ClstrDspdSASWrnng_HS 1 "Warning" 0 "No Warning" ;
VAL_ 1047 ClstrDspdSCSWrnng_HS 1 "Warning" 0 "No Warning" ;
VAL_ 1047 ClstrDspdScurtKeyBatLW_HS 1 "Warning" 0 "No Warning" ;
VAL_ 1047 ClstrDspdSpStBtnWrnng_HS 1 "Warning" 0 "No Warning" ;
VAL_ 1047 ClstrDspdSpStWrnng_HS 1 "Warning" 0 "No Warning" ;
VAL_ 1047 ClstrDspdTCSWrnng_HS 1 "Warning" 0 "No Warning" ;
VAL_ 1047 ClstrDspdTrWrnng_HS 1 "Warning" 0 "No Warning" ;
VAL_ 1047 ClstrDspdTyrePrsSts_HS 2 "System Failure" 1 "Low Tyre" 0 "No Warning" ;
VAL_ 1144 ClstrDspdFLTireSts_HS 1 "Warning" 0 "No Warning" ;
VAL_ 1144 ClstrDspdFRTireSts_HS 1 "Warning" 0 "No Warning" ;
VAL_ 1144 ClstrDspdRLTireSts_HS 1 "Warning" 0 "No Warning" ;
VAL_ 1144 ClstrDspdRRTireSts_HS 1 "Warning" 0 "No Warning" ;
VAL_ 1144 StabCtrlDsblSwA_HS 1 "TRUE" 0 "FALSE" ;
VAL_ 1531 wake_network_IPK_HS 1 "wake-up network request" 0 "no wake-up network request" ;
VAL_ 1087 sm_network_mode_h1 2 "normal" 1 "shutdown" 0 "start-up" ;
VAL_ 573 FLObsRng_HS 15 "Range 15" 14 "Range 14" 13 "Range 13" 12 "Range 12" 11 "Range 11" 10 "Range 10" 9 "Range 9" 8 "Range 8" 7 "Range 7" 6 "Range 6" 5 "Range 5" 4 "Range 4" 3 "Range 3" 2 "Range 2" 1 "Range 1" 0 "No Obstacle" ;
VAL_ 573 FRObsRng_HS 15 "Range 15" 14 "Range 14" 13 "Range 13" 12 "Range 12" 11 "Range 11" 10 "Range 10" 9 "Range 9" 8 "Range 8" 7 "Range 7" 6 "Range 6" 5 "Range 5" 4 "Range 4" 3 "Range 3" 2 "Range 2" 1 "Range 1" 0 "No Obstacle" ;
VAL_ 573 FrtMidLObsRng_HS 15 "Range 15" 14 "Range 14" 13 "Range 13" 12 "Range 12" 11 "Range 11" 10 "Range 10" 9 "Range 9" 8 "Range 8" 7 "Range 7" 6 "Range 6" 5 "Range 5" 4 "Range 4" 3 "Range 3" 2 "Range 2" 1 "Range 1" 0 "No Obstacle" ;
VAL_ 573 FrtMidRObsRng_HS 15 "Range 15" 14 "Range 14" 13 "Range 13" 12 "Range 12" 11 "Range 11" 10 "Range 10" 9 "Range 9" 8 "Range 8" 7 "Range 7" 6 "Range 6" 5 "Range 5" 4 "Range 4" 3 "Range 3" 2 "Range 2" 1 "Range 1" 0 "No Obstacle" ;
VAL_ 573 PDCCofignSts_HS 7 "Reserved" 6 "Reserved" 5 "Reserved" 4 "2 rear sensors" 3 "4 rear sensors and 4 front sensors" 2 "4 rear sensors and 2 front side sensors" 1 "4 rear sensors" 0 "3 rear sensors" ;
VAL_ 573 PDCSysSts_HS 7 "Rear PDC Disabled" 6 "Rear PDC Failed" 5 "Front PDC Failed" 4 "Front PDC Disabled" 3 "System Disabled" 2 "System Failed" 1 "System initialization sucessful" 0 "System OK" ;
VAL_ 573 RLObsRng_HS 15 "Range 15" 14 "Range 14" 13 "Range 13" 12 "Range 12" 11 "Range 11" 10 "Range 10" 9 "Range 9" 8 "Range 8" 7 "Range 7" 6 "Range 6" 5 "Range 5" 4 "Range 4" 3 "Range 3" 2 "Range 2" 1 "Range 1" 0 "No Obstacle" ;
VAL_ 573 RrMidLObsRng_HS 15 "Range 15" 14 "Range 14" 13 "Range 13" 12 "Range 12" 11 "Range 11" 10 "Range 10" 9 "Range 9" 8 "Range 8" 7 "Range 7" 6 "Range 6" 5 "Range 5" 4 "Range 4" 3 "Range 3" 2 "Range 2" 1 "Range 1" 0 "No Obstacle" ;
VAL_ 573 RrMidRObsRng_HS 15 "Range 15" 14 "Range 14" 13 "Range 13" 12 "Range 12" 11 "Range 11" 10 "Range 10" 9 "Range 9" 8 "Range 8" 7 "Range 7" 6 "Range 6" 5 "Range 5" 4 "Range 4" 3 "Range 3" 2 "Range 2" 1 "Range 1" 0 "No Obstacle" ;
VAL_ 573 RRObsRng_HS 15 "Range 15" 14 "Range 14" 13 "Range 13" 12 "Range 12" 11 "Range 11" 10 "Range 10" 9 "Range 9" 8 "Range 8" 7 "Range 7" 6 "Range 6" 5 "Range 5" 4 "Range 4" 3 "Range 3" 2 "Range 2" 1 "Range 1" 0 "No Obstacle" ;
VAL_ 485 StrgWhlAngSnsrCalSts_HS 3 "Unkonw" 2 "Calibrated" 1 "Estimated" 0 "Unkonw" ;
VAL_ 485 StrgWhlAngSnsrFlt_HS 1 "TRUE" 0 "FALSE" ;
VAL_ 455 AutoHoldSysSts_HS 3 "error" 2 "standby" 1 "intervention" 0 "Off" ;
VAL_ 562 HDCSysSts_HS 4 "Temporarily Inhibited" 3 "Failed" 2 "Active" 1 "Enabled" 0 "Normal" ;
VAL_ 532 BrkFludLvlLow_HS 1 "TRUE" 0 "FALSE" ;
VAL_ 532 BrkFludLvlLowV_HS 1 "Invalid" 0 "Valid" ;
VAL_ 840 WhlGndVelLDrvnV_HS 1 "Invalid" 0 "Valid" ;
VAL_ 840 WhlGndVelRDrvnV_HS 1 "Invalid" 0 "Valid" ;
VAL_ 842 WhlGndVelLNonDrvnV_HS 1 "Invalid" 0 "Valid" ;
VAL_ 842 WhlGndVelRNonDrvnV_HS 1 "Invalid" 0 "Valid" ;
VAL_ 381 ABSIO_HS 1 "TRUE" 0 "FALSE" ;
VAL_ 381 BrkSysRedBrkTlltReq_HS 1 "TRUE" 0 "FALSE" ;
VAL_ 381 TCSOpngMd_HS 2 "Off Road" 1 "Normal" 0 "Off" ;
VAL_ 381 TCSOpngSts_HS 2 "Fault" 1 "Active" 0 "Inactive" ;
VAL_ 381 VSEMd_HS 2 "Competitive" 1 "Normal" 0 "Off" ;
VAL_ 381 VSESts_HS 4 "Not Ready" 3 "Warming Up" 2 "Fault" 1 "Active" 0 "Inactive" ;
VAL_ 837 AutoHoldMsg_HS 7 "reserved" 6 "reserved" 5 "Autohold release" 4 "Autohold off" 3 "Autohold standby" 2 "Press brake pedal" 1 "Seat belt not fastend" 0 "reserved" ;
VAL_ 851 DistRCAvgDrvnV_HS 1 "Invalid" 0 "Valid" ;
VAL_ 851 VehSpdAvgDrvnV_HS 1 "Invalid" 0 "Valid" ;
VAL_ 355 AirbagSysFltIndCmd_HS 3 "reserved" 2 "drive lamp Flashing" 1 "drive lamp ON  " 0 "drive lamp OFF" ;
VAL_ 355 FasnDrvrSbltIndCmd_HS 3 "Signal not available" 2 "drive lamp Flashing" 1 "drive lamp ON  " 0 "drive lamp OFF" ;
VAL_ 355 FasnFrtPsngSbltIndCmd_HS 3 "Signal not available" 2 "drive lamp Flashing" 1 "drive lamp ON  " 0 "drive lamp OFF" ;
VAL_ 355 FasnSbltAudRmndr_HS 1 "TRUE" 0 "FALSE" ;
VAL_ 355 FasnSecRowLSbltIndCmd_HS 3 "Reserved" 2 "Flashing Indication" 1 "On Indication" 0 "Off Indication" ;
VAL_ 355 FasnSecRowMidSbltIndC_HS 3 "Reserved" 2 "Flashing Indication" 1 "On Indication" 0 "Off Indication" ;
VAL_ 355 FasnSecRowRSbltIndCmd_HS 3 "Reserved" 2 "Flashing Indication" 1 "On Indication" 0 "Off Indication" ;
VAL_ 1225 TrNonEmsnRltdMalfA_HS 1 "TRUE" 0 "FALSE" ;
VAL_ 1072 keep_network_TPMS_HS 1 "keep network request" 0 "no keep network request" ;
VAL_ 1149 FLTirePrsV_HS 1 "Invalid" 0 "Valid" ;
VAL_ 1149 FLTireTemV_HS 1 "Invalid" 0 "Valid" ;
VAL_ 1149 FRTirePrsV_HS 1 "Invalid" 0 "Valid" ;
VAL_ 1149 FRTireTemV_HS 1 "Invalid" 0 "Valid" ;
VAL_ 1149 RLTirePrsV_HS 1 "Invalid" 0 "Valid" ;
VAL_ 1149 RLTireTemV_HS 1 "Invalid" 0 "Valid" ;
VAL_ 1149 RRTirePrsV_HS 1 "Invalid" 0 "Valid" ;
VAL_ 1149 RRTireTemV_HS 1 "Invalid" 0 "Valid" ;
VAL_ 1150 FLTireSts_HS 7 "Battery Low" 6 "Axle Pressure imbalance" 5 "Temperature High" 4 "Pressure High" 3 "Quick leak" 2 "Pressure Low" 1 "Unkown" 0 "Normal" ;
VAL_ 1150 FRTireSts_HS 7 "Battery Low" 6 "Axle Pressure imbalance" 5 "Temperature High" 4 "Pressure High" 3 "Quick leak" 2 "Pressure Low" 1 "Unkown" 0 "Normal" ;
VAL_ 1150 RLTireSts_HS 7 "Battery Low" 6 "Axle Pressure imbalance" 5 "Temperature High" 4 "Pressure High" 3 "Quick leak" 2 "Pressure Low" 1 "Unkown" 0 "Normal" ;
VAL_ 1150 RRTireSts_HS 7 "Battery Low" 6 "Axle Pressure imbalance" 5 "Temperature High" 4 "Pressure High" 3 "Quick leak" 2 "Pressure Low" 1 "Unkown" 0 "Normal" ;
VAL_ 1150 TPMSAutoLoctnCm_HS 1 "TRUE" 0 "FALSE" ;
VAL_ 1150 TPMSF_HS 1 "TRUE" 0 "FALSE" ;
VAL_ 1150 TPMSIdficnLrnCm_HS 1 "TRUE" 0 "FALSE" ;
VAL_ 1150 TPMSTirePrsLowIO_HS 1 "TRUE" 0 "FALSE" ;
VAL_ 1150 TPMSWntrMdA_HS 1 "TRUE" 0 "FALSE" ;
VAL_ 1060 wake_network_TPMS_HS 1 "wake-up network request" 0 "no wake-up network request" ;
